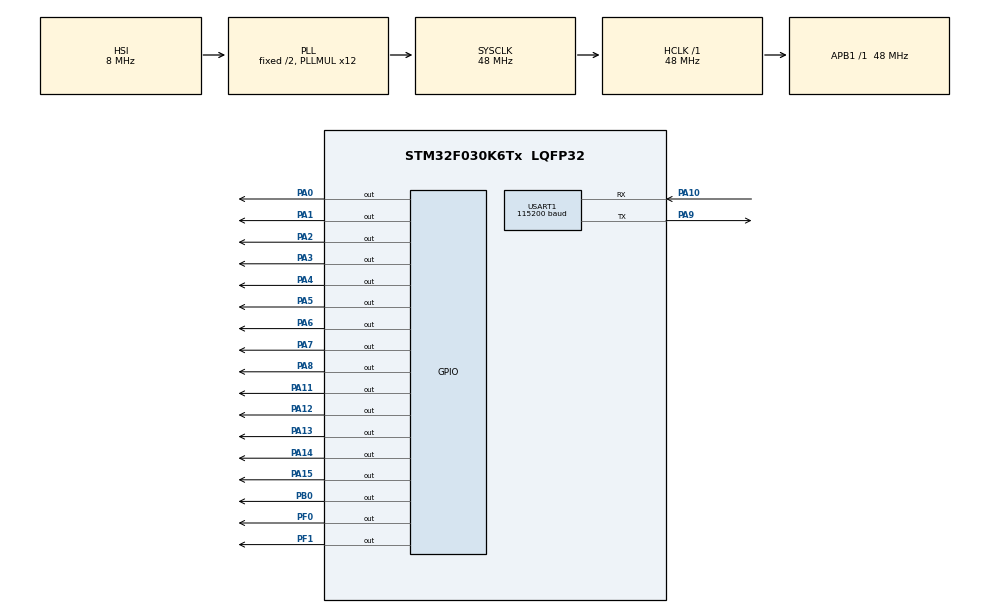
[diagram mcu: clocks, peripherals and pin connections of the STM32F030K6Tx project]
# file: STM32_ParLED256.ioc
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Dma.Request0=TIM1_CH1
Dma.Request1=TIM1_CH2
Dma.Request2=TIM1_CH4/TRIG/COM
Dma.Request3=TIM1_CH3/UP
Dma.TIM1_CH1.0.Direction=DMA_MEMORY_TO_PERIPH
Dma.TIM1_CH1.0.Instance=DMA1_Channel2
Dma.TIM1_CH1.0.MemDataAlignment=DMA_MDATAALIGN_WORD
Dma.TIM1_CH1.0.MemInc=DMA_MINC_ENABLE
Dma.TIM1_CH1.0.Mode=DMA_CIRCULAR
Dma.TIM1_CH1.0.PeriphDataAlignment=DMA_PDATAALIGN_WORD
Dma.TIM1_CH1.0.PeriphInc=DMA_PINC_DISABLE
Dma.TIM1_CH1.0.Priority=DMA_PRIORITY_HIGH
Dma.TIM1_CH2.1.Direction=DMA_MEMORY_TO_PERIPH
Dma.TIM1_CH2.1.Instance=DMA1_Channel3
Dma.TIM1_CH2.1.MemDataAlignment=DMA_MDATAALIGN_WORD
Dma.TIM1_CH2.1.MemInc=DMA_MINC_ENABLE
Dma.TIM1_CH2.1.Mode=DMA_CIRCULAR
Dma.TIM1_CH2.1.PeriphDataAlignment=DMA_PDATAALIGN_WORD
Dma.TIM1_CH2.1.PeriphInc=DMA_PINC_DISABLE
Dma.TIM1_CH2.1.Priority=DMA_PRIORITY_HIGH
Dma.TIM1_CH3/UP.3.Direction=DMA_MEMORY_TO_PERIPH
Dma.TIM1_CH3/UP.3.Instance=DMA1_Channel5
Dma.TIM1_CH3/UP.3.MemDataAlignment=DMA_MDATAALIGN_WORD
Dma.TIM1_CH3/UP.3.MemInc=DMA_MINC_ENABLE
Dma.TIM1_CH3/UP.3.Mode=DMA_CIRCULAR
Dma.TIM1_CH3/UP.3.PeriphDataAlignment=DMA_PDATAALIGN_WORD
Dma.TIM1_CH3/UP.3.PeriphInc=DMA_PINC_DISABLE
Dma.TIM1_CH3/UP.3.Priority=DMA_PRIORITY_HIGH
Dma.TIM1_CH4/TRIG/COM.2.Direction=DMA_MEMORY_TO_PERIPH
Dma.TIM1_CH4/TRIG/COM.2.Instance=DMA1_Channel4
Dma.TIM1_CH4/TRIG/COM.2.MemDataAlignment=DMA_MDATAALIGN_WORD
Dma.TIM1_CH4/TRIG/COM.2.MemInc=DMA_MINC_ENABLE
Dma.TIM1_CH4/TRIG/COM.2.Mode=DMA_CIRCULAR
Dma.TIM1_CH4/TRIG/COM.2.PeriphDataAlignment=DMA_PDATAALIGN_WORD
Dma.TIM1_CH4/TRIG/COM.2.PeriphInc=DMA_PINC_DISABLE
Dma.TIM1_CH4/TRIG/COM.2.Priority=DMA_PRIORITY_HIGH
Mcu.Family=STM32F0
Mcu.Name=STM32F030K6Tx
Mcu.Package=LQFP32
NVIC.DMA1_Channel2_3_IRQn=true\:0\:0\:false\:false\:true\:false\:true\:true
NVIC.DMA1_Channel4_5_IRQn=true\:0\:0\:false\:false\:true\:false\:true\:true
NVIC.TIM1_BRK_UP_TRG_COM_IRQn=true\:1\:0\:true\:false\:true\:true\:true\:true
NVIC.TIM3_IRQn=true\:0\:0\:false\:false\:true\:true\:true\:true
PA0.GPIO_ModeDefaultOutputPP=GPIO_MODE_OUTPUT_PP
PA0.GPIO_PuPd=GPIO_NOPULL
PA0.GPIO_Speed=GPIO_SPEED_FREQ_HIGH
PA0.Signal=GPIO_Output
PA1.GPIO_Speed=GPIO_SPEED_FREQ_HIGH
PA1.Signal=GPIO_Output
PA10.Mode=Asynchronous
PA10.Signal=USART1_RX
PA11.GPIO_Speed=GPIO_SPEED_FREQ_HIGH
PA11.Signal=GPIO_Output
PA12.GPIO_Speed=GPIO_SPEED_FREQ_HIGH
PA12.Signal=GPIO_Output
PA13.GPIO_Speed=GPIO_SPEED_FREQ_HIGH
PA13.Signal=GPIO_Output
PA14.GPIO_Speed=GPIO_SPEED_FREQ_HIGH
PA14.Signal=GPIO_Output
PA15.GPIO_Speed=GPIO_SPEED_FREQ_HIGH
PA15.Signal=GPIO_Output
PA2.GPIO_Speed=GPIO_SPEED_FREQ_HIGH
PA2.Signal=GPIO_Output
PA3.GPIO_Speed=GPIO_SPEED_FREQ_HIGH
PA3.Signal=GPIO_Output
PA4.GPIO_Speed=GPIO_SPEED_FREQ_HIGH
PA4.Signal=GPIO_Output
PA5.GPIO_Speed=GPIO_SPEED_FREQ_HIGH
PA5.Signal=GPIO_Output
PA6.GPIO_Speed=GPIO_SPEED_FREQ_HIGH
PA6.Signal=GPIO_Output
PA7.GPIO_Speed=GPIO_SPEED_FREQ_HIGH
PA7.Signal=GPIO_Output
PA8.GPIO_Speed=GPIO_SPEED_FREQ_HIGH
PA8.Signal=GPIO_Output
PA9.Mode=Asynchronous
PA9.Signal=USART1_TX
PB0.GPIO_Speed=GPIO_SPEED_FREQ_HIGH
PB0.Signal=GPIO_Output
PF0-OSC_IN.GPIO_Speed=GPIO_SPEED_FREQ_HIGH
PF0-OSC_IN.Signal=GPIO_Output
PF1-OSC_OUT.GPIO_Speed=GPIO_SPEED_FREQ_HIGH
PF1-OSC_OUT.Signal=GPIO_Output
ProjectManager.HeapSize=0x200
ProjectManager.StackSize=0x400
ProjectManager.TargetToolchain=CMake
RCC.AHBFreq_Value=48000000
RCC.APB1Freq_Value=48000000
RCC.APB1TimFreq_Value=48000000
RCC.HCLKFreq_Value=48000000
RCC.PLLMUL=RCC_PLL_MUL12
RCC.SYSCLKFreq_VALUE=48000000
RCC.SYSCLKSource=RCC_SYSCLKSOURCE_PLLCLK
TIM1.Channel-Output\ Compare1\ No\ Output=TIM_CHANNEL_1
TIM1.Channel-Output\ Compare2\ No\ Output=TIM_CHANNEL_2
TIM1.Channel-Output\ Compare3\ No\ Output=TIM_CHANNEL_3
TIM1.Channel-Output\ Compare4\ No\ Output=TIM_CHANNEL_4
TIM1.Period=999
TIM1.Prescaler=5
TIM3.Period=19999
USART1.BaudRate=115200
USART1.VirtualMode-Asynchronous=VM_ASYNC
VP_TIM1_VS_ClockSourceINT.Mode=Internal
VP_TIM1_VS_no_output1.Mode=Output Compare1 No Output
VP_TIM1_VS_no_output2.Mode=Output Compare2 No Output
VP_TIM1_VS_no_output3.Mode=Output Compare3 No Output
VP_TIM1_VS_no_output4.Mode=Output Compare4 No Output
VP_TIM3_VS_ClockSourceINT.Mode=Internal
board=custom

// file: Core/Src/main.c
/* USER CODE BEGIN Header */
/**
  ******************************************************************************
  * @file           : main.c
  * @brief          : Main program body
  ******************************************************************************
  * @attention
  *
  * Copyright (c) 2025 STMicroelectronics.
  * All rights reserved.
  *
  * This software is licensed under terms that can be found in the LICENSE file
  * in the root directory of this software component.
  * If no LICENSE file comes with this software, it is provided AS-IS.
  *
  ******************************************************************************
  */
/* USER CODE END Header */
#include "main.h"

/* USER CODE BEGIN PM */
#include "main.h"
#include "matrixLED.h"

#define NUM_FRAMES 536

const uint16_t led_animation[NUM_FRAMES][16] ={
  { 0xFF0F, 0xFF87, 0xFF07, 0xFE07, 0xFE03, 0xFE03, 0xFE03, 0xFF03, 0xFF03, 0xF883, 0xF883, 0xF887, 0xFC03, 0xFC07, 0xFC03, 0xFC01 },
  { 0xFF0F, 0xFF87, 0xFF07, 0xFE07, 0xFE03, 0xFE03, 0xFE03, 0xFF03, 0xFF03, 0xF883, 0xF883, 0xF887, 0xFC03, 0xFC07, 0xFC07, 0xFC01 },
  { 0xFF0F, 0xFF87, 0xFF07, 0xFE07, 0xFE03, 0xFE03, 0xFE03, 0xFF03, 0xFF03, 0xF983, 0xF883, 0xF887, 0xFC03, 0xFC07, 0xFC07, 0xFC01 },
  { 0xFF0F, 0xFF87, 0xFF07, 0xFE07, 0xFE03, 0xFE03, 0xFE03, 0xFF03, 0xFF03, 0xF9C3, 0xF943, 0xF887, 0xF803, 0xFC07, 0xFC07, 0xFC01 },
  { 0xFF0F, 0xFF07, 0xFF07, 0xFE07, 0xFE03, 0xFE03, 0xFE03, 0xFF03, 0xFF03, 0xFDC3, 0xF943, 0xF887, 0xF803, 0xFC07, 0xFC07, 0xFC05 },
  { 0xFF0F, 0xFF07, 0xFF07, 0xFE07, 0xFE03, 0xFE03, 0xFE03, 0xFF03, 0xFF03, 0xF943, 0xF943, 0xF987, 0xF803, 0xFC07, 0xFC07, 0xFC07 },
  { 0xFF0F, 0xFF07, 0xFF07, 0xFE07, 0xFE03, 0xFE03, 0xFE03, 0xFF03, 0xFF03, 0xFF43, 0xF943, 0xF987, 0xF803, 0xF807, 0xFC07, 0xFC07 },
  { 0xFE0F, 0xFF07, 0xFF07, 0xFE07, 0xFE03, 0xFE03, 0xFE03, 0xFF03, 0xFF03, 0xFF03, 0xF943, 0xF987, 0xF883, 0xF887, 0xFC07, 0xFC07 },
  { 0xFE0F, 0xFF07, 0xFE07, 0xFE07, 0xFE03, 0xFE03, 0xFE03, 0xFF03, 0xFF03, 0xFF03, 0xF947, 0xF987, 0xF983, 0xF887, 0xFC07, 0xFC07 },
  { 0xFE0F, 0xFE07, 0xFE07, 0xFE07, 0xFE03, 0xFE03, 0xFE03, 0xFF03, 0xFF03, 0xFF03, 0xFB47, 0xF187, 0xF183, 0xF887, 0xFC07, 0xFC07 },
  { 0xFE0F, 0xFE07, 0xFE07, 0xFE07, 0xFE03, 0xFE03, 0xFE03, 0xFF03, 0xFF03, 0xFF03, 0xFF03, 0xF387, 0xF183, 0xF087, 0xF807, 0xFC07 },
  { 0xFC0F, 0xFE0F, 0xFE07, 0xFE07, 0xFC03, 0xFC03, 0xFE03, 0xFF03, 0xFF03, 0xFF03, 0xFF03, 0xFB87, 0xF383, 0xF187, 0xF007, 0xF807 },
  { 0xFC0F, 0xFC0F, 0xFE07, 0xFC07, 0xFC07, 0xFC03, 0xFC03, 0xFF03, 0xFF03, 0xFF03, 0xFF07, 0xFF87, 0xF383, 0xE387, 0xE183, 0xF003 },
  { 0xFC0F, 0xFC0F, 0xFE07, 0xFC07, 0xFC07, 0xFC03, 0xFC03, 0xFF03, 0xFF03, 0xFF03, 0xFF07, 0xFF07, 0xFF83, 0xE783, 0xE383, 0xE003 },
  { 0xF81F, 0xFC0F, 0xFE07, 0xFC07, 0xFC07, 0xFC07, 0xFC03, 0xFE03, 0xFF03, 0xFF03, 0xFF07, 0xFF07, 0xFF83, 0xF783, 0xE783, 0xE007 },
  { 0xF81F, 0xF80F, 0xFC0F, 0xFC07, 0xFC07, 0xFC07, 0xFC03, 0xFE03, 0xFF03, 0xFF03, 0xFF07, 0xFF03, 0xFF03, 0xFF83, 0xE787, 0xE781 },
  { 0xF81F, 0xF80F, 0xFC0F, 0xFC07, 0xFC07, 0xFC07, 0xFC07, 0xFE03, 0xFF03, 0xFF03, 0xFF07, 0xFF03, 0xFF03, 0xFF87, 0xFF81, 0xE781 },
  { 0xF91F, 0xF80F, 0xF80F, 0xFC07, 0xFC07, 0xFC07, 0xFC07, 0xFC03, 0xFF03, 0xFF03, 0xFF03, 0xFF03, 0xFF03, 0xFF01, 0xFF81, 0xFF81 },
  { 0xFF9F, 0xF80F, 0xF80F, 0xFC07, 0xFC07, 0xFC07, 0xFC07, 0xFC03, 0xFF03, 0xFF83, 0xFF83, 0xFF83, 0xFF83, 0xFF81, 0xFF81, 0xFF83 },
  { 0xFF9F, 0xF80F, 0xF80F, 0xFC07, 0xFC07, 0xFC07, 0xFC07, 0xFC03, 0xFE03, 0xFF03, 0xFF83, 0xFEC3, 0xFF83, 0xFF81, 0xFF81, 0xFF81 },
  { 0xFFFF, 0xFC0F, 0xF80F, 0xFC07, 0xFC07, 0xFC07, 0xFC07, 0xFC03, 0xFE03, 0xFF03, 0xFF83, 0xFEC3, 0xFFC3, 0xFF83, 0xFF81, 0xFF81 },
  { 0xFFFF, 0xFE8F, 0xFC0F, 0xFC07, 0xFE07, 0xFC07, 0xFC07, 0xFC03, 0xFE03, 0xFF03, 0xFF03, 0xFEC3, 0xFEC3, 0xFFC1, 0xFFC1, 0xFFC1 },
  { 0xFFFF, 0xFFCF, 0xFC07, 0xFC07, 0xFE07, 0xFE03, 0xFE03, 0xFE03, 0xFE03, 0xFF03, 0xFF03, 0xFF03, 0xFEE1, 0xFFC1, 0xFFC1, 0xFFC0 },
  { 0xFFFF, 0xFFEF, 0xFE07, 0xFE07, 0xFE03, 0xFE03, 0xFE03, 0xFE03, 0xFE03, 0xFF03, 0xFF03, 0xFF23, 0xFF61, 0xFFE1, 0xFFC1, 0xFFC0 },
  { 0xFFFF, 0xFFFF, 0xFF07, 0xFF03, 0xFF03, 0xFF03, 0xFE03, 0xFE03, 0xFE01, 0xFF81, 0xFF81, 0xFF21, 0xFF61, 0xFF61, 0xFFE0, 0xFFC0 },
  { 0xFFFF, 0xFFFF, 0xFF87, 0xFF03, 0xFF83, 0xFF01, 0xFF01, 0xFF01, 0xFF01, 0xFF81, 0xFF81, 0xFF81, 0xFF21, 0xFF60, 0xFF60, 0xFFE0 },
  { 0xFFFF, 0xFFFF, 0xFFCB, 0xFF81, 0xFF81, 0xFF81, 0xFF01, 0xFF01, 0xFF01, 0xFF81, 0xFFC1, 0xFF81, 0xFFB1, 0xFFB0, 0xFF60, 0xFFE0 },
  { 0xFFFF, 0xFFFF, 0xFFC7, 0xFFC1, 0xFF81, 0xFF80, 0xFF80, 0xFF80, 0xFF80, 0xFFC0, 0xFFC0, 0xFFC0, 0xFF90, 0xFFB0, 0xFFF0, 0xFFE0 },
  { 0xFFFF, 0xFFF7, 0xFFE1, 0xFFE0, 0xFFC0, 0xFF80, 0xFF80, 0xFF80, 0xFFC0, 0xFFC0, 0xFFC0, 0xFFD0, 0xFFD0, 0xFFD0, 0xFFF0, 0xFFF0 },
  { 0xFFFF, 0xFFF3, 0xFFF0, 0xFFE0, 0xFFC0, 0xFFC0, 0xFFC0, 0xFFC0, 0xFFC0, 0xFFE0, 0xFFE0, 0xFFE0, 0xFFE0, 0xFFF0, 0xFFF0, 0xFFF0 },
  { 0xFFF9, 0xFFF8, 0xFFF0, 0xFFE0, 0xFFC0, 0xFFC0, 0xFFC0, 0xFFE0, 0xFFE0, 0xFFE0, 0xFFE0, 0xFFE0, 0xFFF8, 0xFFF8, 0xFFF8, 0xFFF0 },
  { 0xFFFC, 0xFFF8, 0xFFF0, 0xFFE0, 0xFFE0, 0xFFE0, 0xFFE0, 0xFFE0, 0xFFF0, 0xFFF0, 0xFFF8, 0xFFF8, 0xFFF8, 0xFFF8, 0xFFF8, 0xFFF8 },
  { 0xFFFE, 0xFFF8, 0xFFF0, 0xFFF0, 0xFFE0, 0xFFE0, 0xFFF0, 0xFFF0, 0xFFF0, 0xFFF0, 0xFFF0, 0xFFF8, 0xFFF8, 0xFFF8, 0xFFF8, 0xFFF8 },
  { 0xFFFF, 0xFFF8, 0xFFF0, 0xFFF0, 0xFFF0, 0xFFF0, 0xFFF0, 0xFFF0, 0xFFF8, 0xFFFC, 0xFFF8, 0xFFF8, 0xFFF8, 0xFFF8, 0xFFF0, 0xFFF8 },
  { 0xFFFF, 0xFFFC, 0xFFF8, 0xFFF8, 0xFFF8, 0xFFF8, 0xFFF8, 0xFFF8, 0xFFF8, 0xFFF8, 0xFFF8, 0xFFF8, 0xFFF8, 0xFFF0, 0xFFE0, 0xFFE0 },
  { 0xFFFF, 0xFFFC, 0xFFFC, 0xFFF8, 0xFFF8, 0xFFF8, 0xFFF8, 0xFFFC, 0xFFFE, 0xFFF8, 0xFFF8, 0xFFF0, 0xFFE0, 0xFFC0, 0xFF80, 0xFF00 },
  { 0xFFFF, 0xFFFE, 0xFFFC, 0xFFFC, 0xFFFC, 0xFFFC, 0xFFFC, 0xFFFC, 0xFFFC, 0xFFF0, 0xFFC0, 0xFF00, 0xEC00, 0xC400, 0xC000, 0xE000 },
  { 0xFFFF, 0xFFFE, 0xFFFC, 0xFFFC, 0xFFFC, 0xFFFC, 0xFFFC, 0xCFFC, 0xC5FC, 0xC000, 0xC000, 0xC000, 0xE810, 0xF810, 0xF810, 0xF800 },
  { 0xFFFF, 0xE7FE, 0xE7FC, 0xC7FC, 0xE1FC, 0xE0F8, 0xC078, 0xF80C, 0xF004, 0xF000, 0xE020, 0xE030, 0xE020, 0xE020, 0xE020, 0xFE60 },
  { 0xE07F, 0xF07F, 0xFE3E, 0xFC3C, 0xF81C, 0xF018, 0xE008, 0xE000, 0xE004, 0xE030, 0xF030, 0xF870, 0xFE70, 0xFFE0, 0xFFE0, 0xFFE0 },
  { 0xFF3F, 0xFFBF, 0xFF1F, 0xE01F, 0xE01E, 0xE01C, 0xF00C, 0xF00C, 0xF800, 0xF800, 0xFC20, 0xFC78, 0xFFF0, 0xFFF0, 0xFFF0, 0xFFF0 },
  { 0xFFDF, 0xFFCF, 0xFFCF, 0xF9CF, 0xF9CF, 0xF80F, 0xFC0F, 0xFC0E, 0xFC0E, 0xFC0E, 0xFC04, 0xFC00, 0xFC00, 0xFE00, 0xFFF8, 0xFFF8 },
  { 0xFFFF, 0xFFFF, 0xFFFF, 0xFFFF, 0xFFF7, 0xFF77, 0xFF27, 0xFF27, 0xFF27, 0xFE07, 0xFE0F, 0xFE06, 0xFE06, 0xFE06, 0xFE00, 0xFE00 },
  { 0xFFFF, 0xFFFF, 0xFFFF, 0xFFFF, 0xFFFF, 0xFFFF, 0xFFFF, 0xFFFF, 0xFFFB, 0xFFC3, 0xFFC7, 0xFF87, 0xFF87, 0xFF87, 0xFF07, 0xFF07 },
  { 0xFFFF, 0xFFFF, 0xFFFF, 0xFFFF, 0xFFFF, 0xFFFF, 0xFFFF, 0xFFFF, 0xFFFF, 0xFFFF, 0xFFFF, 0xFFFF, 0xFFF9, 0xFFF1, 0xFFF3, 0xFFE3 },
  { 0xFFFF, 0xFFFF, 0xFFFF, 0xFFFF, 0xFFFF, 0xFFFF, 0xFFFF, 0xFFFF, 0xFFFF, 0xFFFF, 0xFFFF, 0xFFFF, 0xFFFF, 0xFFFF, 0xFFFF, 0xFFFF },
  { 0xFFFF, 0xFFFF, 0xFFFF, 0xFFFF, 0xFFFF, 0xFFFF, 0xFFFF, 0xFFFF, 0xFFFF, 0xFFFF, 0xFFFF, 0xFFFF, 0xFFFF, 0xFFFF, 0xFFFF, 0xFFFF },
  { 0xFCFF, 0xFFFF, 0xFFFF, 0xFFFF, 0xFFFF, 0xFFFF, 0xFFFF, 0xFFFF, 0xFFFF, 0xFFFF, 0xFFFF, 0xFFFF, 0xFFFF, 0xFFFF, 0xFFFF, 0xFFFF },
  { 0xFCFF, 0xFCFF, 0xFFFF, 0xFFFF, 0xFFFF, 0xFFFF, 0xFFFF, 0xFFFF, 0xFFFF, 0xFFFF, 0xFFFF, 0xFFFF, 0xFFFF, 0xFFFF, 0xFFFF, 0xFFFF },
  { 0xFC7F, 0xFCFF, 0xFFFF, 0xFFFF, 0xFFFF, 0xFFFF, 0xFFFF, 0xFFFF, 0xFFFF, 0xFFFF, 0xFFFF, 0xFFFF, 0xFFFF, 0xFFFF, 0xFFFF, 0xFFFF },
  { 0xFC7F, 0xFC7F, 0xFCFF, 0xFFFF, 0xFFFF, 0xFFFF, 0xFFFF, 0xFFFF, 0xFFFF, 0xFFFF, 0xFFFF, 0xFFFF, 0xFFFF, 0xFFFF, 0xFFFF, 0xFFFF },
  { 0xFC7F, 0xFC7F, 0xFC7F, 0xFE7F, 0xFFFF, 0xFFFF, 0xFFFF, 0xFFFF, 0xFFFF, 0xFFFF, 0xFFFF, 0xFFFF, 0xFFFF, 0xFFFF, 0xFFFF, 0xFFFF },
  { 0xFEFF, 0xFC7F, 0xFC7F, 0xFC7F, 0xFE7F, 0xFFFF, 0xFFFF, 0xFFFF, 0xFFFF, 0xFFFF, 0xFFFF, 0xFFFF, 0xFFFF, 0xFFFF, 0xFFFF, 0xFFFF },
  { 0xFFFF, 0xFE7F, 0xFC7F, 0xFC7F, 0xFC7F, 0xFFFF, 0xFFFF, 0xFFFF, 0xFFFF, 0xFFFF, 0xFFFF, 0xFFFF, 0xFFFF, 0xFFFF, 0xFFFF, 0xFFFF },
  { 0xFFFF, 0xFFFF, 0xFC7F, 0xFC3F, 0xFC3F, 0xFE7F, 0xFFFF, 0xFFFF, 0xFFFF, 0xFFFF, 0xFFFF, 0xFFFF, 0xFFFF, 0xFFFF, 0xFFFF, 0xFFFF },
  { 0xFFFF, 0xFFFF, 0xFE7F, 0xFC3F, 0xFC3F, 0xFC3F, 0xFE7F, 0xFFFF, 0xFFFF, 0xFFFF, 0xFFFF, 0xFFFF, 0xFFFF, 0xFFFF, 0xFFFF, 0xFFFF },
  { 0xFFFF, 0xFFFF, 0xFFFF, 0xFE7F, 0xFC3F, 0xFC3F, 0xFE7F, 0xFF7F, 0xFFFF, 0xFFFF, 0xFFFF, 0xFFFF, 0xFFFF, 0xFFFF, 0xFFFF, 0xFFFF },
  { 0xFFFF, 0xFFFF, 0xFFFF, 0xFE7F, 0xFE3F, 0xFC3F, 0xFC3F, 0xFE7F, 0xFFFF, 0xFFFF, 0xFFFF, 0xFFFF, 0xFFFF, 0xFFFF, 0xFFFF, 0xFFFF },
  { 0xFFFF, 0xFFFF, 0xFFFF, 0xFFFF, 0xFE3F, 0xFC3F, 0xFC3F, 0xFE3F, 0xFE7F, 0xFFFF, 0xFFFF, 0xFFFF, 0xFFFF, 0xFFFF, 0xFFFF, 0xFFFF },
  { 0xFFFF, 0xFFFF, 0xFFFF, 0xFFFF, 0xFF7F, 0xFE3F, 0xFC3F, 0xFC3F, 0xFE3F, 0xFF7F, 0xFFFF, 0xFFFF, 0xFFFF, 0xFFFF, 0xFFFF, 0xFFFF },
  { 0xFFFF, 0xFFFF, 0xFFFF, 0xFFFF, 0xFFFF, 0xFE3F, 0xFE3F, 0xFE3F, 0xFE3F, 0xFE7F, 0xFFFF, 0xFFFF, 0xFFFF, 0xFFFF, 0xFFFF, 0xFFFF },
  { 0xFFFF, 0xFFFF, 0xFFFF, 0xFFFF, 0xFFFF, 0xFF7F, 0xFC3F, 0xFE3F, 0xFE3F, 0xFE3F, 0xFFFF, 0xFFFF, 0xFFFF, 0xFFFF, 0xFFFF, 0xFFFF },
  { 0xFFFF, 0xFFFF, 0xFFFF, 0xFFFF, 0xFFFF, 0xFFFF, 0xFE3F, 0xFC3F, 0xFE3F, 0xFE3F, 0xFE3F, 0xFFFF, 0xFFFF, 0xFFFF, 0xFFFF, 0xFFFF },
  { 0xFFFF, 0xFFFF, 0xFFFF, 0xFFFF, 0xFFFF, 0xFFFF, 0xFE7F, 0xFE3F, 0xFE1F, 0xFE1F, 0xFE3F, 0xFFFF, 0xFFFF, 0xFFFF, 0xFFFF, 0xFFFF },
  { 0xFFFF, 0xFFFF, 0xFFFF, 0xFFFF, 0xFFFF, 0xFFFF, 0xFFFF, 0xFE3F, 0xFE1F, 0xFE1F, 0xFE3F, 0xFF3F, 0xFFFF, 0xFFFF, 0xFFFF, 0xFFFF },
  { 0xFFFF, 0xFFFF, 0xFFFF, 0xFFFF, 0xFFFF, 0xFFFF, 0xFFFF, 0xFF3F, 0xFE1F, 0xFE1F, 0xFE1F, 0xFF3F, 0xFFFF, 0xFFFF, 0xFFFF, 0xFFFF },
  { 0xFFFF, 0xFFFF, 0xFFFF, 0xFFFF, 0xFFFF, 0xFFFF, 0xFFFF, 0xFF3F, 0xFE1F, 0xFE1F, 0xFE1F, 0xFE3F, 0xFE3F, 0xFFFF, 0xFFFF, 0xFFFF },
  { 0xFFFF, 0xFFFF, 0xFFFF, 0xFFFF, 0xFFFF, 0xFFFF, 0xFFFF, 0xFFFF, 0xFE3F, 0xFE1F, 0xFE1F, 0xFE1F, 0xFF3F, 0xFFFF, 0xFFFF, 0xFFFF },
  { 0xFFFF, 0xFFFF, 0xFFFF, 0xFFFF, 0xFFFF, 0xFFFF, 0xFFFF, 0xFFFF, 0xFF3F, 0xFE1F, 0xFE1F, 0xFE1F, 0xFE3F, 0xFFFF, 0xFFFF, 0xFFFF },
  { 0xFFFF, 0xFFFF, 0xFFFF, 0xFFFF, 0xFFFF, 0xFFFF, 0xFFFF, 0xFFFF, 0xFF3F, 0xFE3F, 0xFE1F, 0xFE1F, 0xFE3F, 0xFF3F, 0xFFFF, 0xFFFF },
  { 0xFFFF, 0xFFFF, 0xFFFF, 0xFFFF, 0xFFFF, 0xFFFF, 0xFFFF, 0xFFFF, 0xFF7F, 0xFE3F, 0xFE1F, 0xFE1F, 0xFE3F, 0xFF7F, 0xFFFF, 0xFFFF },
  { 0xFFFF, 0xFFFF, 0xFFFF, 0xFFFF, 0xFFFF, 0xFFFF, 0xFFFF, 0xFFFF, 0xFF7F, 0xFE3F, 0xFE1F, 0xFE1F, 0xFE3F, 0xFF1F, 0xFFFF, 0xFFFF },
  { 0xFFFF, 0xFFFF, 0xFFFF, 0xFFFF, 0xFFFF, 0xFFFF, 0xFFFF, 0xFFFF, 0xFFFF, 0xFE3F, 0xFE1F, 0xFE1F, 0xFE1F, 0xFF3F, 0xFFFF, 0xFFFF },
  { 0xFFFF, 0xFFFF, 0xFFFF, 0xFFFF, 0xFFFF, 0xFFFF, 0xFFFF, 0xFFFF, 0xFFFF, 0xFE1F, 0xFE1F, 0xFE1F, 0xFE1F, 0xFF3F, 0xFFFF, 0xFFFF },
  { 0xFFFF, 0xFFFF, 0xFFFF, 0xFFFF, 0xFFFF, 0xFFFF, 0xFFFF, 0xFFFF, 0xFFBF, 0xFE3F, 0xFE1F, 0xFE1F, 0xFE1F, 0xFF3F, 0xFFFF, 0xFFFF },
  { 0xFFFF, 0xFFFF, 0xFFFF, 0xFFFF, 0xFFFF, 0xFFFF, 0xFFFF, 0xFFFF, 0xFF3F, 0xFE1F, 0xFE1F, 0xFE1F, 0xFE1F, 0xFF3F, 0xFFFF, 0xFFFF },
  { 0xFFFF, 0xFFFF, 0xFFFF, 0xFFFF, 0xFFFF, 0xFFFF, 0xFFFF, 0xFFFF, 0xFF3F, 0xFE3F, 0xFE1F, 0xFE1F, 0xFE1F, 0xFF3F, 0xFFFF, 0xFFFF },
  { 0xFFFF, 0xFFFF, 0xFFFF, 0xFFFF, 0xFFFF, 0xFFFF, 0xFFFF, 0xFFFF, 0xFE3F, 0xFE1F, 0xFE1F, 0xFE1F, 0xFE3F, 0xFF7F, 0xFFFF, 0xFFFF },
  { 0xFFFF, 0xFFFF, 0xFFFF, 0xFFFF, 0xFFFF, 0xFFFF, 0xFFFF, 0xFFFF, 0xFE3F, 0xFE1F, 0xFE1F, 0xFE1F, 0xFE3F, 0xFFFF, 0xFFFF, 0xFFFF },
  { 0xFFFF, 0xFFFF, 0xFFFF, 0xFFFF, 0xFFFF, 0xFFFF, 0xFFFF, 0xFF3F, 0xFE1F, 0xFE1F, 0xFE1F, 0xFE1F, 0xFE3F, 0xFFFF, 0xFFFF, 0xFFFF },
  { 0xFFFF, 0xFFFF, 0xFFFF, 0xFFFF, 0xFFFF, 0xFFFF, 0xFFFF, 0xFF3F, 0xFE1F, 0xFE1F, 0xFE1F, 0xFE1F, 0xFF7F, 0xFFFF, 0xFFFF, 0xFFFF },
  { 0xFFFF, 0xFFFF, 0xFFFF, 0xFFFF, 0xFFFF, 0xFFFF, 0xFF7F, 0xFE3F, 0xFE1F, 0xFC1F, 0xFE1F, 0xFE3F, 0xFFFF, 0xFFFF, 0xFFFF, 0xFFFF },
  { 0xFFFF, 0xFFFF, 0xFFFF, 0xFFFF, 0xFFFF, 0xFFFF, 0xFF3F, 0xFC3F, 0xFE1F, 0xFC1F, 0xFE3F, 0xFF3F, 0xFFFF, 0xFFFF, 0xFFFF, 0xFFFF },
  { 0xFFFF, 0xFFFF, 0xFFFF, 0xFFFF, 0xFFFF, 0xFFFF, 0xFE3F, 0xFE1F, 0xFE1F, 0xFE1F, 0xFE3F, 0xFFFF, 0xFFFF, 0xFFFF, 0xFFFF, 0xFFFF },
  { 0xFFFF, 0xFFFF, 0xFFFF, 0xFFFF, 0xFFFF, 0xFF7F, 0xFE3F, 0xFE1F, 0xFC1F, 0xFE1F, 0xFE3F, 0xFFFF, 0xFFFF, 0xFFFF, 0xFFFF, 0xFFFF },
  { 0xFFFF, 0xFFFF, 0xFFFF, 0xFFFF, 0xFFFF, 0xFE3F, 0xFC3F, 0xFC1F, 0xFE1F, 0xFE3F, 0xFE7F, 0xFFFF, 0xFFFF, 0xFFFF, 0xFFFF, 0xFFFF },
  { 0xFFFF, 0xFFFF, 0xFFFF, 0xFFFF, 0xFFFF, 0xFE3F, 0xFC1F, 0xFC1F, 0xFE1F, 0xFC3F, 0xFF7F, 0xFFFF, 0xFFFF, 0xFFFF, 0xFFFF, 0xFFFF },
  { 0xFFFF, 0xFFFF, 0xFFFF, 0xFFFF, 0xFF7F, 0xFE3F, 0xFC1F, 0xFC1F, 0xFE3F, 0xFE3F, 0xFFFF, 0xFFFF, 0xFFFF, 0xFFFF, 0xFFFF, 0xFFFF },
  { 0xFFFF, 0xFFFF, 0xFFFF, 0xFFFF, 0xFE3F, 0xFE3F, 0xFC1F, 0xFC1F, 0xFC3F, 0xFF3F, 0xFFFF, 0xFFFF, 0xFFFF, 0xFFFF, 0xFFFF, 0xFFFF },
  { 0xFFFF, 0xFFFF, 0xFFFF, 0xFFFF, 0xFE3F, 0xFE3F, 0xFC1F, 0xFC1F, 0xFC3F, 0xFF7F, 0xFFFF, 0xFFFF, 0xFFFF, 0xFFFF, 0xFFFF, 0xFFFF },
  { 0xFFFF, 0xFFFF, 0xFFFF, 0xFFFF, 0xFE3F, 0xFC3F, 0xFC1F, 0xFC1F, 0xFE3F, 0xFFFF, 0xFFFF, 0xFFFF, 0xFFFF, 0xFFFF, 0xFFFF, 0xFFFF },
  { 0xFFFF, 0xFFFF, 0xFFFF, 0xFF7F, 0xFE3F, 0xFC3F, 0xFC1F, 0xFC1F, 0xFE3F, 0xFEBF, 0xFFFF, 0xFFFF, 0xFFFF, 0xFFFF, 0xFFFF, 0xFFFF },
  { 0xFFFF, 0xFFFF, 0xFFFF, 0xFFFF, 0xFE3F, 0xFC1F, 0xFC1F, 0xFC3F, 0xFE3F, 0xFF7F, 0xFFFF, 0xFFFF, 0xFFFF, 0xFFFF, 0xFFFF, 0xFFFF },
  { 0xFFFF, 0xFFFF, 0xFFFF, 0xFFFF, 0xFE3F, 0xFC1F, 0xFC1F, 0xFC3F, 0xFE3F, 0xFF7F, 0xFFFF, 0xFFFF, 0xFFFF, 0xFFFF, 0xFFFF, 0xFFFF },
  { 0xFFFF, 0xFFFF, 0xFFFF, 0xFFFF, 0xFE3F, 0xFC3F, 0xFC3F, 0xFC3F, 0xFE3F, 0xFF3F, 0xFFFF, 0xFFFF, 0xFFFF, 0xFFFF, 0xFFFF, 0xFFFF },
  { 0xFFFF, 0xFFFF, 0xFFFF, 0xFFFF, 0xFE3F, 0xFC3F, 0xFC1F, 0xFC1F, 0xFE3F, 0xFF7F, 0xFFFF, 0xFFFF, 0xFFFF, 0xFFFF, 0xFFFF, 0xFFFF },
  { 0xFFFF, 0xFFFF, 0xFFFF, 0xFFFF, 0xFE3F, 0xFC1F, 0xFC1F, 0xFC1F, 0xFE1F, 0xFE7F, 0xFFFF, 0xFFFF, 0xFFFF, 0xFFFF, 0xFFFF, 0xFFFF },
  { 0xFFFF, 0xFFFF, 0xFFFF, 0xFFFF, 0xFE1F, 0xFE3F, 0xFC1F, 0xFC1F, 0xFE1F, 0xFE3F, 0xFFFF, 0xFFFF, 0xFFFF, 0xFFFF, 0xFFFF, 0xFFFF },
  { 0xFFFF, 0xFFFF, 0xFFFF, 0xFFFF, 0xFE3F, 0xFE1F, 0xFC1F, 0xFC1F, 0xFE1F, 0xFE3F, 0xFFFF, 0xFFFF, 0xFFFF, 0xFFFF, 0xFFFF, 0xFFFF },
  { 0xFFFF, 0xFFFF, 0xFFFF, 0xFFFF, 0xFE3F, 0xFE1F, 0xFC1F, 0xFC1F, 0xFE1F, 0xFE3F, 0xFFFF, 0xFFFF, 0xFFFF, 0xFFFF, 0xFFFF, 0xFFFF },
  { 0xFFFF, 0xFFFF, 0xFFFF, 0xFFFF, 0xFFFF, 0xFE1F, 0xFC1F, 0xFE1F, 0xFE1F, 0xFE3F, 0xFFFF, 0xFFFF, 0xFFFF, 0xFFFF, 0xFFFF, 0xFFFF },
  { 0xFFFF, 0xFFFF, 0xFFFF, 0xFFFF, 0xFF3F, 0xFE1F, 0xFC1F, 0xFC1F, 0xFE1F, 0xFE1F, 0xFF7F, 0xFFFF, 0xFFFF, 0xFFFF, 0xFFFF, 0xFFFF },
  { 0xFFFF, 0xFFFF, 0xFFFF, 0xFFFF, 0xFFBF, 0xFE1F, 0xFE1F, 0xFC1F, 0xFE1F, 0xFE1F, 0xFF7F, 0xFFFF, 0xFFFF, 0xFFFF, 0xFFFF, 0xFFFF },
  { 0xFFFF, 0xFFFF, 0xFFFF, 0xFFFF, 0xFFBF, 0xFE1F, 0xFE1F, 0xFC1F, 0xFE1F, 0xFE1F, 0xFF3F, 0xFFFF, 0xFFFF, 0xFFFF, 0xFFFF, 0xFFFF },
  { 0xFFFF, 0xFFFF, 0xFFFF, 0xFFFF, 0xFFFF, 0xFF1F, 0xFE1F, 0xFE0F, 0xFE1F, 0xFE1F, 0xFF3F, 0xFFFF, 0xFFFF, 0xFFFF, 0xFFFF, 0xFFFF },
  { 0xFFFF, 0xFFFF, 0xFFFF, 0xFFFF, 0xFFFF, 0xFF3F, 0xFE1F, 0xFE0F, 0xFE1F, 0xFE1F, 0xFF1F, 0xFFFF, 0xFFFF, 0xFFFF, 0xFFFF, 0xFFFF },
  { 0xFFFF, 0xFFFF, 0xFFFF, 0xFFFF, 0xFFFF, 0xFF3F, 0xFE1F, 0xFE0F, 0xFE0F, 0xFE1F, 0xFE1F, 0xFFFF, 0xFFFF, 0xFFFF, 0xFFFF, 0xFFFF },
  { 0xFFFF, 0xFFFF, 0xFFFF, 0xFFFF, 0xFFFF, 0xFF3F, 0xFE1F, 0xFE0F, 0xFE0F, 0xFE1F, 0xFE1F, 0xFFFF, 0xFFFF, 0xFFFF, 0xFFFF, 0xFFFF },
  { 0xFFFF, 0xFFFF, 0xFFFF, 0xFFFF, 0xFFFF, 0xFF1F, 0xFE1F, 0xFE0F, 0xFE0F, 0xFE1F, 0xFE1F, 0xFF3F, 0xFFFF, 0xFFFF, 0xFFFF, 0xFFFF },
  { 0xFFFF, 0xFFFF, 0xFFFF, 0xFFFF, 0xFFFF, 0xFFBF, 0xFE1F, 0xFE0F, 0xFE0F, 0xFE1F, 0xFE1F, 0xFF3F, 0xFFFF, 0xFFFF, 0xFFFF, 0xFFFF },
  { 0xFFFF, 0xFFFF, 0xFFFF, 0xFFFF, 0xFFFF, 0xFFBF, 0xFF1F, 0xFE0F, 0xFE0F, 0xFE0F, 0xFE1F, 0xFF3F, 0xFFFF, 0xFFFF, 0xFFFF, 0xFFFF },
  { 0xFFFF, 0xFFFF, 0xFFFF, 0xFFFF, 0xFFFF, 0xFFBF, 0xFF1F, 0xFE0F, 0xFE0F, 0xFE0F, 0xFE1F, 0xFF1F, 0xFFFF, 0xFFFF, 0xFFFF, 0xFFFF },
  { 0xFFFF, 0xFFFF, 0xFFFF, 0xFFFF, 0xFFFF, 0xFFFF, 0xFF1F, 0xFE1F, 0xFE0F, 0xFE0F, 0xFE1F, 0xFF1F, 0xFFFF, 0xFFFF, 0xFFFF, 0xFFFF },
  { 0xFFFF, 0xFFFF, 0xFFFF, 0xFFFF, 0xFFFF, 0xFFFF, 0xFE1F, 0xFE1F, 0xFE0F, 0xFE0F, 0xFE1F, 0xFF3F, 0xFFFF, 0xFFFF, 0xFFFF, 0xFFFF },
  { 0xFFFF, 0xFFFF, 0xFFFF, 0xFFFF, 0xFFFF, 0xFFBF, 0xFF1F, 0xFE1F, 0xFE0F, 0xFE0F, 0xFE1F, 0xFF3F, 0xFFFF, 0xFFFF, 0xFFFF, 0xFFFF },
  { 0xFFFF, 0xFFFF, 0xFFFF, 0xFFFF, 0xFFFF, 0xFFFF, 0xFE1F, 0xFE1F, 0xFE0F, 0xFE0F, 0xFE1F, 0xFF3F, 0xFFFF, 0xFFFF, 0xFFFF, 0xFFFF },
  { 0xFFFF, 0xFFFF, 0xFFFF, 0xFFFF, 0xFFFF, 0xFFFF, 0xFE1F, 0xFE1F, 0xFE0F, 0xFE1F, 0xFE1F, 0xFF3F, 0xFFFF, 0xFFFF, 0xFFFF, 0xFFFF },
  { 0xFFFF, 0xFFFF, 0xFFFF, 0xFFFF, 0xFFFF, 0xFFFF, 0xFE1F, 0xFE1F, 0xFE1F, 0xFE1F, 0xFE1F, 0xFF3F, 0xFFFF, 0xFFFF, 0xFFFF, 0xFFFF },
  { 0xFFFF, 0xFFFF, 0xFFFF, 0xFFFF, 0xFFFF, 0xFFFF, 0xFF1F, 0xFE1F, 0xFE1F, 0xFE1F, 0xFE1F, 0xFF1F, 0xFFFF, 0xFFFF, 0xFFFF, 0xFFFF },
  { 0xFFFF, 0xFFFF, 0xFFFF, 0xFFFF, 0xFFFF, 0xFFFF, 0xFF1F, 0xFE1F, 0xFE1F, 0xFE1F, 0xFE1F, 0xFF3F, 0xFFFF, 0xFFFF, 0xFFFF, 0xFFFF },
  { 0xFFFE, 0xFFFF, 0xFFFF, 0xFFFF, 0xFFFF, 0xFFFF, 0xFE1F, 0xFE1F, 0xFE1F, 0xFE1F, 0xFE1F, 0xFE3F, 0xFFFF, 0xFFFF, 0xFFFF, 0xFFFF },
  { 0xF800, 0xFFFF, 0xFFFF, 0xFFFF, 0xFFFF, 0xFFFF, 0xFE3F, 0xFE1F, 0xFE1F, 0xFE1F, 0xFE1F, 0xFE3F, 0xFFFF, 0xFFFF, 0xFFFF, 0xFFFF },
  { 0x0000, 0xC000, 0xFFFC, 0xFFFC, 0xFFFE, 0xFFFF, 0xFE3F, 0xFE1F, 0xFC1F, 0xFE1F, 0xFE1F, 0xFE3F, 0xFFFF, 0xFFFF, 0xFFFF, 0xFFFF },
  { 0x0000, 0x0000, 0x7FC0, 0xFF80, 0xFF80, 0xFFFC, 0xFF3E, 0xFC1E, 0xFC1E, 0xFC1F, 0xFE1F, 0xFE3F, 0xFFFF, 0xFFFF, 0xFFFF, 0xFFFF },
  { 0x0000, 0xFE00, 0xFE00, 0xFF00, 0xFFE0, 0xFFE1, 0xFF20, 0xFE10, 0xFC10, 0xFC10, 0xFE18, 0xFE38, 0xFFFC, 0xFFFF, 0xFFFF, 0xFFFF },
  { 0x00FF, 0x01FF, 0x01FF, 0x008F, 0x0087, 0x0086, 0x01C2, 0x01C0, 0x03E0, 0x03E0, 0x01E0, 0x00E0, 0x0000, 0x0000, 0x0000, 0x0000 },
  { 0x00FF, 0x01FF, 0x01FF, 0x008F, 0x0087, 0x0086, 0x01C2, 0x01C0, 0x03E0, 0x03E0, 0x01E0, 0x00E0, 0x0000, 0x0000, 0x0000, 0x0000 },
  { 0x00FF, 0x01FF, 0x01FF, 0x008F, 0x0087, 0x0086, 0x01C2, 0x01C0, 0x03E0, 0x03E0, 0x01E0, 0x00E0, 0x0000, 0x0000, 0x0000, 0x0000 },
  { 0x00FF, 0x01FF, 0x01FF, 0x008F, 0x0087, 0x0086, 0x01C2, 0x01C0, 0x03E0, 0x03E0, 0x01E0, 0x00E0, 0x0000, 0x0000, 0x0000, 0x0000 },
  { 0x00FF, 0x01FF, 0x01FF, 0x008F, 0x0087, 0x0086, 0x01C2, 0x01C0, 0x03E0, 0x03E0, 0x01E0, 0x00E0, 0x0000, 0x0000, 0x0000, 0x0000 },
  { 0x00FF, 0x01FF, 0x01FF, 0x008F, 0x0087, 0x0086, 0x01C2, 0x01C0, 0x03E0, 0x03E0, 0x01E0, 0x00E0, 0x0000, 0x0000, 0x0000, 0x0000 },
  { 0x00FF, 0x01FF, 0x01FF, 0x008F, 0x0087, 0x0086, 0x01C2, 0x01C0, 0x03E0, 0x03E0, 0x01E0, 0x00E0, 0x0000, 0x0000, 0x0000, 0x0000 },
  { 0x00FF, 0x01FF, 0x01FF, 0x008F, 0x0087, 0x0086, 0x01C2, 0x01C0, 0x03E0, 0x03E0, 0x01E0, 0x00E0, 0x0000, 0x0000, 0x0000, 0x0000 },
  { 0x00FF, 0x01FF, 0x01FF, 0x008F, 0x0087, 0x0086, 0x01C2, 0x01C0, 0x03E0, 0x03E0, 0x01E0, 0x00E0, 0x0000, 0x0000, 0x0000, 0x0000 },
  { 0x00FF, 0x01FF, 0x01FF, 0x008F, 0x0087, 0x0086, 0x01C2, 0x01C0, 0x03E0, 0x03E0, 0x01E0, 0x00E0, 0x0000, 0x0000, 0x0000, 0x0000 },
  { 0x00FF, 0x01FF, 0x01FF, 0x008F, 0x0087, 0x0086, 0x01C2, 0x01C0, 0x03E0, 0x03E0, 0x01E0, 0x00E0, 0x0000, 0x0000, 0x0000, 0x0000 },
  { 0x00FF, 0x01FF, 0x01FF, 0x008F, 0x0087, 0x0086, 0x01C2, 0x01C0, 0x03E0, 0x03E0, 0x01E0, 0x00E0, 0x0000, 0x0000, 0x0000, 0x0000 },
  { 0x00FF, 0x01FF, 0x01FF, 0x008F, 0x0087, 0x0086, 0x01C2, 0x01C0, 0x03E0, 0x03E0, 0x01E0, 0x00E0, 0x0000, 0x0000, 0x0000, 0x0000 },
  { 0x00FF, 0x01FF, 0x01FF, 0x008F, 0x0087, 0x0086, 0x01C2, 0x01C0, 0x03E0, 0x03E0, 0x01E0, 0x00E0, 0x0000, 0x0000, 0x0000, 0x0000 },
  { 0x3FFF, 0x07FF, 0x07FF, 0x03FF, 0x03FE, 0x07FC, 0x07F8, 0x07D0, 0x07C0, 0x07C0, 0x03C0, 0x0100, 0x0000, 0x0000, 0x0000, 0x0000 },
  { 0xFFFF, 0x3FFF, 0x1FFF, 0x0FFF, 0x1FFC, 0x3FF8, 0x7EF0, 0x7E20, 0x7E10, 0x3E00, 0x1C00, 0x0000, 0x0000, 0x0000, 0x0000, 0x0000 },
  { 0x7FFF, 0xFFFF, 0xFFFF, 0x1FFF, 0x1FFB, 0xFFF9, 0xFBF0, 0xF860, 0xF810, 0xF800, 0xF800, 0x2000, 0x0000, 0x0000, 0x0000, 0x0000 },
  { 0x6FFF, 0xFFFF, 0xFFFF, 0xFFFF, 0x7FFF, 0x7FFF, 0x7FF7, 0xE0F0, 0xE0C0, 0xE000, 0xE000, 0xC000, 0x0000, 0x0000, 0x0000, 0x0000 },
  { 0xFFC4, 0xBFED, 0x9FFF, 0xFFFF, 0xFFFF, 0xFFFF, 0xFFFF, 0x7FFF, 0x0D07, 0x0100, 0x0000, 0x0000, 0x0000, 0x0000, 0x0000, 0x0000 },
  { 0xFF80, 0xFF88, 0xFF80, 0xFFBF, 0xFFFF, 0xFFFF, 0xFFFF, 0xFFFF, 0xFFFF, 0xFE1F, 0x0201, 0x0200, 0x0000, 0x0000, 0x0000, 0x0000 },
  { 0xCC00, 0xEE00, 0xFE00, 0xFE00, 0xFF07, 0xFFFF, 0xFFFF, 0xFFFF, 0xFFFF, 0xFFFF, 0xFC7F, 0x040F, 0x0400, 0x0000, 0x0000, 0x0000 },
  { 0x0800, 0x9800, 0x9800, 0xFC00, 0xFC00, 0xFC0F, 0xFE7F, 0xFFFF, 0xFFFF, 0xFFFF, 0xFFFF, 0xFFFF, 0x081F, 0x0801, 0x0000, 0x0000 },
  { 0x0000, 0x1000, 0x3000, 0x3000, 0xF000, 0xF100, 0xFF1E, 0xFCFF, 0xFFFF, 0xFFFF, 0xFFFF, 0xFFFF, 0xFFFF, 0x3C1F, 0x1002, 0x0000 },
  { 0x0000, 0x0000, 0x2000, 0x6000, 0x6000, 0xF000, 0xF800, 0xF87C, 0xFFFE, 0xFFFE, 0xFFFF, 0xFFFF, 0xFFFF, 0xF8FE, 0x300E, 0x0002 },
  { 0x8000, 0x0000, 0x4000, 0xE000, 0xE000, 0xE000, 0xB000, 0xF070, 0xFFFC, 0xFFFC, 0xFFFE, 0xFFFF, 0xFFFF, 0xFBFF, 0x7038, 0x2000 },
  { 0x8000, 0x0000, 0x4000, 0xC000, 0xC000, 0xC000, 0xA000, 0xF470, 0xFFF8, 0xFFFC, 0xFFFE, 0xFFFE, 0xFFFE, 0xF3FE, 0xF078, 0x4000 },
  { 0x0000, 0x8000, 0x4000, 0xC000, 0xC000, 0xE000, 0xB000, 0xD420, 0xFFF8, 0xFFFC, 0xFFFE, 0xFFFE, 0xFFFF, 0xF3FF, 0xF078, 0x4004 },
  { 0x8000, 0x8000, 0x8000, 0x6000, 0xE000, 0xE000, 0xF000, 0xE800, 0xFFFC, 0xFFFC, 0xFFFE, 0xFFFF, 0xFFFF, 0xFBFF, 0xF0FD, 0x200C },
  { 0xC000, 0xC000, 0xE000, 0xE000, 0x7000, 0xF000, 0xF800, 0xEC00, 0xF77C, 0xFFFE, 0xFFFF, 0xFFFF, 0xFFFF, 0xFFFF, 0xF8FF, 0x7816 },
  { 0xC000, 0xE000, 0xE000, 0xF000, 0xB800, 0xF800, 0xF800, 0xFE00, 0xFC1C, 0xFDFF, 0xFFFF, 0xFFFF, 0xFFFF, 0xFFFF, 0xFCFF, 0xFC1F },
  { 0xE000, 0xF800, 0xF800, 0xFC00, 0xFC00, 0xFC00, 0xFC00, 0xFE00, 0xFE00, 0xFEFF, 0xFFFF, 0xFFFF, 0xFFFF, 0xFFFF, 0xFFFF, 0xFE3F },
  { 0xFC00, 0xFE00, 0xFC00, 0xFE00, 0xF600, 0xFE00, 0xFE00, 0xFE00, 0x7FE0, 0x7E47, 0x7FFF, 0xFFFF, 0xFFFF, 0xFFFF, 0xFFFF, 0xFFBF },
  { 0xFF00, 0xFF00, 0xFF00, 0xFE00, 0xFD00, 0xFF00, 0xFB80, 0xFF80, 0xFFC0, 0x9F70, 0xBFDF, 0xFFFF, 0xFFFF, 0xFFFF, 0xFFFF, 0xFFFF },
  { 0xFF80, 0x3FC0, 0x3F60, 0x7F80, 0x7F00, 0x7FC0, 0x7FC0, 0xFFC0, 0xFFC0, 0xEFF8, 0x4FE7, 0xDFFF, 0xFFFF, 0xFFFF, 0x7FFF, 0x7FFF },
  { 0x3FF0, 0x1FF8, 0x0FC0, 0x1FA0, 0x1FC0, 0x9F60, 0x9F70, 0xDFF0, 0x7FF0, 0x37F8, 0x17FF, 0x27FF, 0x6FFF, 0xFFFF, 0xFFFF, 0x3FFF },
  { 0x1FFC, 0x0FFE, 0x07F0, 0x07C0, 0xC7E0, 0xC7A0, 0xEFB0, 0x77FC, 0x1FFC, 0x1FFC, 0x0DFF, 0x1BF9, 0x13FF, 0xB7FF, 0xFFFF, 0x1FFF },
  { 0x07FE, 0x07FF, 0x03FA, 0x03FC, 0x33F0, 0x73E0, 0x73E8, 0x1BEE, 0x0FFE, 0x07FE, 0x06FF, 0x04FE, 0x0DFF, 0x09FF, 0xFFFF, 0xFFFF },
  { 0x03FE, 0x03FF, 0x03FE, 0x00FE, 0x18FD, 0x39FC, 0x19F4, 0x0DF5, 0x07F7, 0x03FF, 0x01FF, 0x027F, 0x027F, 0x04FF, 0x8DFF, 0xFFFF },
  { 0x03FF, 0x01FF, 0x01FF, 0x00FF, 0x0CFF, 0x0CFC, 0x0CF8, 0x0EFA, 0x03FB, 0x01FF, 0x00FF, 0x01BF, 0x013F, 0x027F, 0x02FF, 0xFFFF },
  { 0x03FF, 0x01FF, 0x00FF, 0x007F, 0x047F, 0x067E, 0x0E7E, 0x06F8, 0x017F, 0x01FF, 0x00FF, 0x009F, 0x009F, 0x013F, 0x013F, 0xC37F },
  { 0x03FF, 0x01FF, 0x00FF, 0x00FF, 0x003F, 0x067D, 0x067E, 0x077C, 0x01FD, 0x00FD, 0x007F, 0x005F, 0x009F, 0x009F, 0x013F, 0x037F },
  { 0x03FF, 0x01FF, 0x00FF, 0x007F, 0x003F, 0x033F, 0x073E, 0x037F, 0x01FD, 0x00FF, 0x007F, 0x007F, 0x004F, 0x00CF, 0x009F, 0x01BF },
  { 0x03FF, 0x01FF, 0x00FF, 0x007F, 0x003F, 0x031F, 0x033F, 0x033F, 0x01BE, 0x00FE, 0x007F, 0x002F, 0x006F, 0x004F, 0x00CF, 0x009F },
  { 0x03FF, 0x01FF, 0x00FF, 0x007F, 0x001F, 0x011F, 0x031F, 0x033F, 0x01BE, 0x00FE, 0x007F, 0x003F, 0x002F, 0x0067, 0x004F, 0x00CF },
  { 0x03FF, 0x01FF, 0x00FF, 0x007F, 0x003F, 0x011F, 0x039F, 0x039F, 0x01BF, 0x00FF, 0x007F, 0x003F, 0x003F, 0x0027, 0x0067, 0x004F },
  { 0x03FF, 0x01FF, 0x00FF, 0x007F, 0x003F, 0x001F, 0x019F, 0x039F, 0x019F, 0x00FF, 0x007F, 0x003F, 0x003F, 0x0027, 0x0067, 0x0047 },
  { 0x03FF, 0x01FF, 0x00FF, 0x007F, 0x003F, 0x003F, 0x019F, 0x039F, 0x019F, 0x00FF, 0x005F, 0x007F, 0x003F, 0x0037, 0x0027, 0x0067 },
  { 0x03FF, 0x01FF, 0x00FF, 0x007F, 0x003F, 0x003F, 0x019F, 0x039F, 0x019F, 0x00DF, 0x007F, 0x007F, 0x003F, 0x003F, 0x0027, 0x0027 },
  { 0x03FF, 0x03FF, 0x01FF, 0x007F, 0x007F, 0x003F, 0x019F, 0x039F, 0x039F, 0x01DF, 0x007F, 0x007F, 0x003F, 0x003F, 0x0037, 0x0027 },
  { 0x07FF, 0x03FF, 0x01FF, 0x00FF, 0x007F, 0x003F, 0x019F, 0x038F, 0x039F, 0x019F, 0x007F, 0x005F, 0x007F, 0x003F, 0x003F, 0x0027 },
  { 0x07FF, 0x07FF, 0x01FF, 0x01FF, 0x007F, 0x003F, 0x01BF, 0x039F, 0x039F, 0x019F, 0x00DF, 0x007F, 0x007F, 0x007F, 0x003F, 0x0027 },
  { 0x0FFE, 0x07FF, 0x03FF, 0x01FF, 0x007F, 0x007F, 0x013F, 0x039F, 0x039F, 0x019F, 0x00DF, 0x007F, 0x007F, 0x007F, 0x007F, 0x003F },
  { 0x0FFF, 0x07FF, 0x03FF, 0x01FF, 0x00FF, 0x007F, 0x013F, 0x039F, 0x039F, 0x039F, 0x00DF, 0x007F, 0x007F, 0x007F, 0x007F, 0x007F },
  { 0x0FFF, 0x07FF, 0x03FF, 0x01FF, 0x00FF, 0x007F, 0x007F, 0x01BF, 0x039F, 0x039F, 0x009F, 0x007F, 0x007F, 0x007F, 0x007F, 0x007F },
  { 0x0FFF, 0x07FF, 0x03FF, 0x01FF, 0x00FF, 0x007F, 0x007F, 0x01BF, 0x039F, 0x039F, 0x019F, 0x00FF, 0x007F, 0x007F, 0x007F, 0x007F },
  { 0x0FFF, 0x07FF, 0x03FF, 0x01FF, 0x00FF, 0x007F, 0x007F, 0x01BF, 0x039F, 0x039F, 0x019F, 0x007F, 0x007F, 0x007F, 0x007F, 0x007F },
  { 0x07FF, 0x07FF, 0x03FF, 0x01FF, 0x00FF, 0x007F, 0x007F, 0x01BF, 0x039F, 0x039F, 0x019F, 0x005F, 0x007F, 0x007F, 0x007F, 0x007F },
  { 0x07FF, 0x07FF, 0x03FF, 0x01FF, 0x00FF, 0x007F, 0x007F, 0x01BF, 0x039F, 0x019F, 0x01DF, 0x005F, 0x007F, 0x007F, 0x007F, 0x007F },
  { 0x07FF, 0x07FF, 0x03FF, 0x01FF, 0x00FF, 0x00FF, 0x007F, 0x01FF, 0x01BF, 0x019F, 0x01DF, 0x005F, 0x007F, 0x007F, 0x007F, 0x007F },
  { 0x07FF, 0x07FF, 0x03FF, 0x01FF, 0x00FF, 0x00FF, 0x007F, 0x00FF, 0x01FF, 0x01DF, 0x01DF, 0x005F, 0x007F, 0x007F, 0x007F, 0x007F },
  { 0x07FF, 0x03FF, 0x03FF, 0x01FF, 0x00FF, 0x00FF, 0x007F, 0x00FF, 0x01FF, 0x01DF, 0x01DF, 0x005F, 0x007F, 0x007F, 0x007F, 0x007F },
  { 0x077F, 0x07FF, 0x03FF, 0x01FF, 0x00FF, 0x00FF, 0x007F, 0x007F, 0x01FF, 0x01DF, 0x01DF, 0x00DF, 0x007F, 0x007F, 0x007F, 0x007F },
  { 0x073F, 0x07FF, 0x03FF, 0x01FF, 0x01FF, 0x00FF, 0x007F, 0x007F, 0x00FF, 0x01DF, 0x01DF, 0x00DF, 0x007F, 0x007F, 0x007F, 0x007F },
  { 0x0F3F, 0x07FF, 0x03FF, 0x03FF, 0x01FF, 0x00FF, 0x00FF, 0x007F, 0x00FF, 0x01DF, 0x01DF, 0x00DF, 0x007F, 0x007F, 0x003F, 0x003F },
  { 0x0F3F, 0x07FF, 0x07FF, 0x03FE, 0x01FF, 0x00FF, 0x00FF, 0x007F, 0x00FF, 0x01DF, 0x01DF, 0x00FF, 0x007F, 0x003F, 0x003F, 0x003F },
  { 0x0E3F, 0x0FFF, 0x07FF, 0x07FE, 0x03FE, 0x01FF, 0x00FF, 0x007F, 0x00FF, 0x01FF, 0x01DF, 0x00FF, 0x007F, 0x003F, 0x003F, 0x003F },
  { 0x063F, 0x0E7F, 0x0FFF, 0x07FE, 0x03FE, 0x01FF, 0x00FF, 0x007F, 0x00FF, 0x01FF, 0x01DF, 0x00FF, 0x007F, 0x003F, 0x003F, 0x003F },
  { 0x0E3E, 0x167F, 0x1FFF, 0x0FFC, 0x07FC, 0x03FF, 0x01FF, 0x007F, 0x00FF, 0x01FF, 0x01FF, 0x00FF, 0x007F, 0x003F, 0x003F, 0x003F },
  { 0x0E7E, 0x067F, 0x1EFF, 0x1FFC, 0x0FFC, 0x03FF, 0x01FF, 0x00FF, 0x00FF, 0x00FF, 0x01FF, 0x00FF, 0x007F, 0x003F, 0x003F, 0x003F },
  { 0x0F7E, 0x0E7E, 0x06FF, 0x1FFC, 0x1FFC, 0x07FF, 0x01FF, 0x01FF, 0x00FF, 0x00FF, 0x01FF, 0x00FF, 0x007F, 0x003E, 0x003F, 0x003F },
  { 0x0C7C, 0x0E7E, 0x0CFB, 0x07F8, 0x1FFC, 0x0FFF, 0x03FF, 0x01FF, 0x00FF, 0x00FF, 0x01FF, 0x00FF, 0x007F, 0x003E, 0x003E, 0x003F },
  { 0x087C, 0x0C7E, 0x0CFB, 0x07F8, 0x1FF8, 0x1FFF, 0x07FF, 0x01FF, 0x00FF, 0x00FF, 0x01FF, 0x00FF, 0x007D, 0x003E, 0x003E, 0x003F },
  { 0x0038, 0x087E, 0x1CFF, 0x0DF9, 0x1FF8, 0x1FFF, 0x07FF, 0x01FF, 0x00FF, 0x00FF, 0x01FF, 0x00FF, 0x007F, 0x007E, 0x003E, 0x003E },
  { 0x0038, 0x007C, 0x00FE, 0x1DF9, 0x0FF8, 0x1FFE, 0x07FF, 0x01FF, 0x00FF, 0x00FF, 0x01FF, 0x00FF, 0x007E, 0x007F, 0x007F, 0x007F },
  { 0x0010, 0x007C, 0x00FE, 0x0DFB, 0x0FF8, 0x0FFE, 0x07FF, 0x01FF, 0x00FF, 0x01FF, 0x01BF, 0x00FF, 0x007F, 0x007D, 0x007F, 0x007F },
  { 0x0000, 0x0078, 0x00FC, 0x0CF3, 0x0FF8, 0x0FFC, 0x07FF, 0x01FF, 0x00FF, 0x01BF, 0x01BF, 0x00FF, 0x007D, 0x007D, 0x007D, 0x005F },
  { 0x0000, 0x0078, 0x00FC, 0x06F6, 0x0FF0, 0x0FFC, 0x03FF, 0x00FF, 0x00FF, 0x01BF, 0x01BF, 0x007F, 0x007D, 0x007D, 0x007D, 0x005F },
  { 0x0000, 0x0070, 0x02F8, 0x06F6, 0x0FF0, 0x0FFC, 0x03FF, 0x00FF, 0x00FF, 0x01BF, 0x01BF, 0x0079, 0x0078, 0x007F, 0x007F, 0x005F },
  { 0x0000, 0x0030, 0x0278, 0x06F4, 0x0FF0, 0x07F8, 0x01FF, 0x00FE, 0x00FF, 0x01BF, 0x01FF, 0x0078, 0x007A, 0x007F, 0x005F, 0x005F },
  { 0x0000, 0x0000, 0x0278, 0x02FC, 0x0FF0, 0x07F8, 0x01FE, 0x00FE, 0x01FF, 0x01FF, 0x00F3, 0x007A, 0x007B, 0x00FF, 0x005F, 0x009F },
  { 0x0000, 0x0000, 0x0270, 0x06F8, 0x07E0, 0x03F8, 0x01FE, 0x00FC, 0x01FF, 0x01FF, 0x00F1, 0x00FC, 0x00FF, 0x007F, 0x009F, 0x00BF },
  { 0x0000, 0x0000, 0x0070, 0x06F8, 0x07E0, 0x03F0, 0x01FC, 0x00FC, 0x01FE, 0x01FE, 0x00F0, 0x00F6, 0x00FF, 0x003F, 0x00BE, 0x003F },
  { 0x0000, 0x0000, 0x0060, 0x06F0, 0x07E0, 0x03F0, 0x01FC, 0x00FC, 0x01FE, 0x00FE, 0x00F0, 0x00F6, 0x003E, 0x00BF, 0x00BC, 0xC17F },
  { 0x0000, 0x0000, 0x0060, 0x02F0, 0x07E8, 0x03F0, 0x00F8, 0x00FC, 0x017C, 0x00F8, 0x00FC, 0x00BC, 0x00BC, 0x00B9, 0x017F, 0xFFFF },
  { 0x0000, 0x0000, 0x0040, 0x02F0, 0x03E8, 0x01F0, 0x00F8, 0x01F8, 0x017C, 0x00E0, 0x00FC, 0x003C, 0x00BF, 0x007C, 0xFDFF, 0xEFFF },
  { 0x0000, 0x0000, 0x0000, 0x02E0, 0x03C0, 0x01F0, 0x00F8, 0x017C, 0x01FC, 0x00E0, 0x00F8, 0x00BC, 0x00BB, 0xE17F, 0xFFFF, 0x10FF },
  { 0x0000, 0x0000, 0x0000, 0x02E0, 0x03C0, 0x01F0, 0x00F0, 0x0178, 0x00F0, 0x00E8, 0x00F8, 0x00BE, 0x007F, 0xFFFF, 0x10FF, 0x08FF },
  { 0x0000, 0x0000, 0x0000, 0x02E0, 0x03C0, 0x01E0, 0x00F0, 0x0178, 0x00F0, 0x00F8, 0x00F8, 0x00F2, 0xF17F, 0x7FFF, 0x08FF, 0x001D },
  { 0x0000, 0x0000, 0x0000, 0x00E0, 0x03C0, 0x01E0, 0x00F0, 0x0178, 0x00E0, 0x00F0, 0x00B8, 0x007F, 0xFFFF, 0x08FF, 0x003B, 0x0010 },
  { 0x0000, 0x0000, 0x0000, 0x02C0, 0x03C0, 0x01E0, 0x00E0, 0x0170, 0x00D0, 0x00F0, 0x00FC, 0x617F, 0x3FFF, 0x00FF, 0x0031, 0x0000 },
  { 0x0000, 0x0000, 0x0000, 0x02C0, 0x03C0, 0x00E0, 0x0160, 0x00F0, 0x00D0, 0x00F0, 0x0079, 0x7FFF, 0x08FF, 0x0037, 0x0010, 0x0000 },
  { 0x0000, 0x0000, 0x0000, 0x02C0, 0x03C0, 0x00E0, 0x0160, 0x00F0, 0x00D0, 0x00F0, 0x0077, 0x1FFF, 0x04FF, 0x0021, 0x0000, 0x0000 },
  { 0x0000, 0x0000, 0x0000, 0x01C0, 0x03C0, 0x00E0, 0x0160, 0x00E0, 0x00E0, 0x00F8, 0x317F, 0x09FF, 0x0037, 0x0000, 0x0000, 0x0000 },
  { 0x0000, 0x0000, 0x0000, 0x01C0, 0x01C0, 0x00E0, 0x0160, 0x00C0, 0x00E0, 0x0060, 0x3FFF, 0x00FF, 0x0023, 0x0000, 0x0000, 0x0000 },
  { 0x0000, 0x0000, 0x0000, 0x01C0, 0x0180, 0x00E0, 0x0170, 0x00C0, 0x00E0, 0x007E, 0x1FFF, 0x00FF, 0x0023, 0x0000, 0x0000, 0x0000 },
  { 0x0000, 0x0000, 0x0000, 0x01C0, 0x0180, 0x00E0, 0x0160, 0x00E0, 0x00F0, 0x207E, 0x1FFF, 0x002F, 0x0000, 0x0000, 0x0000, 0x0000 },
  { 0x0000, 0x0000, 0x0000, 0x01C0, 0x0180, 0x00E0, 0x01E0, 0x00E0, 0x0070, 0x107E, 0x04FF, 0x0026, 0x0000, 0x0000, 0x0000, 0x0000 },
  { 0x0000, 0x0000, 0x0000, 0x01C0, 0x0180, 0x00E0, 0x01C0, 0x00E0, 0x0070, 0x1DFE, 0x00FF, 0x0022, 0x0000, 0x0000, 0x0000, 0x0000 },
  { 0x0000, 0x0000, 0x0000, 0x0180, 0x0180, 0x00E0, 0x00C0, 0x00E0, 0x0070, 0x1FFE, 0x00DE, 0x0000, 0x0000, 0x0000, 0x0000, 0x0000 },
  { 0x0000, 0x0000, 0x0000, 0x0180, 0x0180, 0x00E0, 0x00C0, 0x00E0, 0x0064, 0x0FFE, 0x001E, 0x0000, 0x0000, 0x0000, 0x0000, 0x0000 },
  { 0x0000, 0x0000, 0x0000, 0x0180, 0x0180, 0x00C0, 0x00C0, 0x0040, 0x006C, 0x0DFE, 0x004E, 0x0000, 0x0000, 0x0000, 0x0000, 0x0000 },
  { 0x0000, 0x0000, 0x0000, 0x0180, 0x0180, 0x00C0, 0x00C0, 0x0040, 0x18FC, 0x04FC, 0x0044, 0x0000, 0x0000, 0x0000, 0x0000, 0x0000 },
  { 0x0000, 0x0000, 0x0000, 0x0080, 0x0180, 0x00C0, 0x00C0, 0x0040, 0x0CFC, 0x00FC, 0x0040, 0x0000, 0x0000, 0x0000, 0x0000, 0x0000 },
  { 0x0000, 0x0000, 0x0000, 0x0000, 0x0180, 0x00C0, 0x0080, 0x0040, 0x0FFC, 0x027C, 0x0000, 0x0000, 0x0000, 0x0000, 0x0000, 0x0000 },
  { 0x0000, 0x0000, 0x0000, 0x0000, 0x0180, 0x00C0, 0x0080, 0x0060, 0x07FC, 0x005C, 0x0000, 0x0000, 0x0000, 0x0000, 0x0000, 0x0000 },
  { 0x0000, 0x0000, 0x0000, 0x0000, 0x0180, 0x00C0, 0x0080, 0x0040, 0x07F8, 0x0048, 0x0000, 0x0000, 0x0000, 0x0000, 0x0000, 0x0000 },
  { 0x0000, 0x0000, 0x0000, 0x0000, 0x0180, 0x00C0, 0x00C0, 0x0040, 0x00F8, 0x0008, 0x0000, 0x0000, 0x0000, 0x0000, 0x0000, 0x0000 },
  { 0x0000, 0x0000, 0x0000, 0x0000, 0x0180, 0x00C0, 0x00C0, 0x00F8, 0x02F8, 0x0000, 0x0000, 0x0000, 0x0000, 0x0000, 0x0000, 0x0000 },
  { 0x0000, 0x0000, 0x0000, 0x0000, 0x0180, 0x00C0, 0x00C0, 0x00F0, 0x00F8, 0x0000, 0x0000, 0x0000, 0x0000, 0x0000, 0x0000, 0x0000 },
  { 0x0000, 0x0000, 0x0000, 0x0000, 0x0180, 0x00C0, 0x00C0, 0x04F0, 0x0078, 0x0000, 0x0000, 0x0000, 0x0000, 0x0000, 0x0000, 0x0000 },
  { 0x0000, 0x0000, 0x0000, 0x0000, 0x0080, 0x00C0, 0x00C0, 0x04F0, 0x0078, 0x0000, 0x0000, 0x0000, 0x0000, 0x0000, 0x0000, 0x0000 },
  { 0x0000, 0x0000, 0x0000, 0x0000, 0x0080, 0x00C0, 0x00C0, 0x06F0, 0x0058, 0x0000, 0x0000, 0x0000, 0x0000, 0x0000, 0x0000, 0x0000 },
  { 0x0000, 0x0000, 0x0000, 0x0000, 0x0080, 0x00C0, 0x00C0, 0x07F0, 0x0050, 0x0000, 0x0000, 0x0000, 0x0000, 0x0000, 0x0000, 0x0000 },
  { 0x0000, 0x0000, 0x0000, 0x0100, 0x0080, 0x00C0, 0x0040, 0x07F0, 0x0050, 0x0000, 0x0000, 0x0000, 0x0000, 0x0000, 0x0000, 0x0000 },
  { 0x0000, 0x0000, 0x0000, 0x0000, 0x0080, 0x00C0, 0x0040, 0x07F0, 0x0050, 0x0000, 0x0000, 0x0000, 0x0000, 0x0000, 0x0000, 0x0000 },
  { 0x0000, 0x0000, 0x0000, 0x0000, 0x0080, 0x00C0, 0x0040, 0x03F0, 0x0040, 0x0000, 0x0000, 0x0000, 0x0000, 0x0000, 0x0000, 0x0000 },
  { 0x0000, 0x0000, 0x0000, 0x0000, 0x0080, 0x00C0, 0x0040, 0x03F0, 0x0040, 0x0000, 0x0000, 0x0000, 0x0000, 0x0000, 0x0000, 0x0000 },
  { 0x0000, 0x0000, 0x0000, 0x0000, 0x0080, 0x00C0, 0x0040, 0x03F0, 0x0040, 0x0000, 0x0000, 0x0000, 0x0000, 0x0000, 0x0000, 0x0000 },
  { 0x0000, 0x0000, 0x0000, 0x0000, 0x0080, 0x00C0, 0x0040, 0x03F0, 0x0040, 0x0000, 0x0000, 0x0000, 0x0000, 0x0000, 0x0000, 0x0000 },
  { 0x0000, 0x0000, 0x0000, 0x0000, 0x0080, 0x00C0, 0x0040, 0x03F0, 0x0000, 0x0000, 0x0000, 0x0000, 0x0000, 0x0000, 0x0000, 0x0000 },
  { 0x0000, 0x0000, 0x0000, 0x0000, 0x0080, 0x00C0, 0x0040, 0x03F0, 0x0000, 0x0000, 0x0000, 0x0000, 0x0000, 0x0000, 0x0000, 0x0000 },
  { 0x0000, 0x0000, 0x0000, 0x0000, 0x0080, 0x00C0, 0x0040, 0x03F0, 0x0000, 0x0000, 0x0000, 0x0000, 0x0000, 0x0000, 0x0000, 0x0000 },
  { 0x0000, 0x0000, 0x0000, 0x0000, 0x0080, 0x00C0, 0x0040, 0x01F0, 0x0000, 0x0000, 0x0000, 0x0000, 0x0000, 0x0000, 0x0000, 0x0000 },
  { 0x0000, 0x0000, 0x0000, 0x0000, 0x0080, 0x00C0, 0x0040, 0x01F0, 0x0000, 0x0000, 0x0000, 0x0000, 0x0000, 0x0000, 0x0000, 0x0000 },
  { 0x0000, 0x0000, 0x0000, 0x0100, 0x0080, 0x00C0, 0x0040, 0x03F0, 0x0000, 0x0000, 0x0000, 0x0000, 0x0000, 0x0000, 0x0000, 0x0000 },
  { 0x0000, 0x0000, 0x0000, 0x0000, 0x0080, 0x00C0, 0x0040, 0x03F0, 0x0000, 0x0000, 0x0000, 0x0000, 0x0000, 0x0000, 0x0000, 0x0000 },
  { 0x0000, 0x0000, 0x0000, 0x0000, 0x0080, 0x00C0, 0x00C0, 0x02F0, 0x0000, 0x0000, 0x0000, 0x0000, 0x0000, 0x0000, 0x0000, 0x0000 },
  { 0x0000, 0x0000, 0x0000, 0x0000, 0x0080, 0x00C0, 0x00C0, 0x02F0, 0x0000, 0x0000, 0x0000, 0x0000, 0x0000, 0x0000, 0x0000, 0x0000 },
  { 0x0000, 0x0000, 0x0000, 0x0080, 0x0080, 0x00C0, 0x0080, 0x02F0, 0x0000, 0x0000, 0x0000, 0x0000, 0x0000, 0x0000, 0x0000, 0x0000 },
  { 0x0000, 0x0000, 0x0000, 0x0180, 0x0080, 0x0080, 0x0080, 0x02F0, 0x0000, 0x0000, 0x0000, 0x0000, 0x0000, 0x0000, 0x0000, 0x0000 },
  { 0x0000, 0x0000, 0x0000, 0x0180, 0x0080, 0x0080, 0x0080, 0x02F0, 0x0000, 0x0000, 0x0000, 0x0000, 0x0000, 0x0000, 0x0000, 0x0000 },
  { 0x0000, 0x0000, 0x0000, 0x0180, 0x0080, 0x0080, 0x0080, 0x00F0, 0x0000, 0x0000, 0x0000, 0x0000, 0x0000, 0x0000, 0x0000, 0x0000 },
  { 0x0000, 0x0000, 0x0000, 0x0180, 0x0080, 0x0080, 0x0080, 0x00F0, 0x0000, 0x0000, 0x0000, 0x0000, 0x0000, 0x0000, 0x0000, 0x0000 },
  { 0x0000, 0x0000, 0x0000, 0x0180, 0x0080, 0x0080, 0x0080, 0x00F0, 0x0000, 0x0000, 0x0000, 0x0000, 0x0000, 0x0000, 0x0000, 0x0000 },
  { 0x0000, 0x0000, 0x0000, 0x0080, 0x0080, 0x0080, 0x00C0, 0x00F0, 0x0000, 0x0000, 0x0000, 0x0000, 0x0000, 0x0000, 0x0000, 0x0000 },
  { 0x0000, 0x0000, 0x0000, 0x0080, 0x0080, 0x0080, 0x00C0, 0x00F0, 0x0000, 0x0000, 0x0000, 0x0000, 0x0000, 0x0000, 0x0000, 0x0000 },
  { 0x0000, 0x0000, 0x0000, 0x0080, 0x0080, 0x0080, 0x0080, 0x02F0, 0x0000, 0x0000, 0x0000, 0x0000, 0x0000, 0x0000, 0x0000, 0x0000 },
  { 0x0000, 0x0000, 0x0000, 0x0080, 0x0080, 0x0080, 0x0090, 0x02F0, 0x0000, 0x0000, 0x0000, 0x0000, 0x0000, 0x0000, 0x0000, 0x0000 },
  { 0x0000, 0x0000, 0x0000, 0x0080, 0x0080, 0x0080, 0x0090, 0x02F0, 0x0000, 0x0000, 0x0000, 0x0000, 0x0000, 0x0000, 0x0000, 0x0000 },
  { 0x0000, 0x0000, 0x0000, 0x0080, 0x0080, 0x0080, 0x0090, 0x00B0, 0x0000, 0x0000, 0x0000, 0x0000, 0x0000, 0x0000, 0x0000, 0x0000 },
  { 0x0000, 0x0000, 0x0000, 0x0080, 0x0080, 0x0080, 0x00B0, 0x00B0, 0x0000, 0x0000, 0x0000, 0x0000, 0x0000, 0x0000, 0x0000, 0x0000 },
  { 0x0000, 0x0000, 0x0000, 0x0080, 0x0080, 0x0080, 0x00B0, 0x00F0, 0x0000, 0x0000, 0x0000, 0x0000, 0x0000, 0x0000, 0x0000, 0x0000 },
  { 0x0000, 0x0000, 0x0000, 0x0080, 0x0080, 0x0080, 0x00B0, 0x02F0, 0x0000, 0x0000, 0x0000, 0x0000, 0x0000, 0x0000, 0x0000, 0x0000 },
  { 0x0000, 0x0000, 0x0000, 0x0080, 0x0080, 0x0080, 0x00B0, 0x02F0, 0x0000, 0x0000, 0x0000, 0x0000, 0x0000, 0x0000, 0x0000, 0x0000 },
  { 0x0000, 0x0000, 0x0000, 0x0080, 0x0080, 0x0080, 0x00B0, 0x02F0, 0x0000, 0x0000, 0x0000, 0x0000, 0x0000, 0x0000, 0x0000, 0x0000 },
  { 0x0000, 0x0000, 0x0000, 0x0080, 0x0080, 0x0080, 0x0090, 0x02F0, 0x0000, 0x0000, 0x0000, 0x0000, 0x0000, 0x0000, 0x0000, 0x0000 },
  { 0x0000, 0x0000, 0x0000, 0x0080, 0x0080, 0x0080, 0x0080, 0x02F0, 0x0000, 0x0000, 0x0000, 0x0000, 0x0000, 0x0000, 0x0000, 0x0000 },
  { 0x0000, 0x0000, 0x0000, 0x0080, 0x0080, 0x0080, 0x0080, 0x02F0, 0x0000, 0x0000, 0x0000, 0x0000, 0x0000, 0x0000, 0x0000, 0x0000 },
  { 0x0000, 0x0000, 0x0000, 0x0080, 0x0080, 0x0080, 0x0080, 0x02F0, 0x0000, 0x0000, 0x0000, 0x0000, 0x0000, 0x0000, 0x0000, 0x0000 },
  { 0x0000, 0x0000, 0x0000, 0x0080, 0x0080, 0x0080, 0x0080, 0x02F0, 0x0000, 0x0000, 0x0000, 0x0000, 0x0000, 0x0000, 0x0000, 0x0000 },
  { 0x0000, 0x0000, 0x0000, 0x0080, 0x0180, 0x0080, 0x00C0, 0x02F0, 0x0000, 0x0000, 0x0000, 0x0000, 0x0000, 0x0000, 0x0000, 0x0000 },
  { 0x0000, 0x0000, 0x0000, 0x0000, 0x0180, 0x0080, 0x00C0, 0x03F0, 0x0000, 0x0000, 0x0000, 0x0000, 0x0000, 0x0000, 0x0000, 0x0000 },
  { 0x0000, 0x0000, 0x0000, 0x0000, 0x0180, 0x0080, 0x00C0, 0x01F0, 0x0000, 0x0000, 0x0000, 0x0000, 0x0000, 0x0000, 0x0000, 0x0000 },
  { 0x0000, 0x0000, 0x0000, 0x0000, 0x0180, 0x0080, 0x00C0, 0x01F0, 0x0000, 0x0000, 0x0000, 0x0000, 0x0000, 0x0000, 0x0000, 0x0000 },
  { 0x0000, 0x0000, 0x0000, 0x0000, 0x0180, 0x0180, 0x00C0, 0x07F0, 0x0000, 0x0000, 0x0000, 0x0000, 0x0000, 0x0000, 0x0000, 0x0000 },
  { 0x0000, 0x0000, 0x0000, 0x0000, 0x0100, 0x0180, 0x0080, 0x07F0, 0x0000, 0x0000, 0x0000, 0x0000, 0x0000, 0x0000, 0x0000, 0x0000 },
  { 0x0000, 0x0000, 0x0000, 0x0000, 0x0100, 0x0180, 0x0080, 0x07F0, 0x0000, 0x0000, 0x0000, 0x0000, 0x0000, 0x0000, 0x0000, 0x0000 },
  { 0x0000, 0x0000, 0x0000, 0x0000, 0x0100, 0x0180, 0x0080, 0x07F0, 0x0010, 0x0000, 0x0000, 0x0000, 0x0000, 0x0000, 0x0000, 0x0000 },
  { 0x0000, 0x0000, 0x0000, 0x0000, 0x0100, 0x0180, 0x0080, 0x07F0, 0x0010, 0x0000, 0x0000, 0x0000, 0x0000, 0x0000, 0x0000, 0x0000 },
  { 0x0000, 0x0000, 0x0000, 0x0000, 0x0100, 0x0180, 0x0080, 0x07F0, 0x0030, 0x0000, 0x0000, 0x0000, 0x0000, 0x0000, 0x0000, 0x0000 },
  { 0x0000, 0x0000, 0x0000, 0x0000, 0x0100, 0x0180, 0x0080, 0x05F0, 0x0030, 0x0000, 0x0000, 0x0000, 0x0000, 0x0000, 0x0000, 0x0000 },
  { 0x0000, 0x0000, 0x0000, 0x0000, 0x0100, 0x0180, 0x0080, 0x05F0, 0x0030, 0x0000, 0x0000, 0x0000, 0x0000, 0x0000, 0x0000, 0x0000 },
  { 0x0000, 0x0000, 0x0000, 0x0000, 0x0100, 0x0180, 0x0080, 0x09F0, 0x0030, 0x0000, 0x0000, 0x0000, 0x0000, 0x0000, 0x0000, 0x0000 },
  { 0x0000, 0x0000, 0x0000, 0x0000, 0x0100, 0x0180, 0x0080, 0x09B0, 0x0030, 0x0000, 0x0000, 0x0000, 0x0000, 0x0000, 0x0000, 0x0000 },
  { 0x0000, 0x0000, 0x0000, 0x0000, 0x0100, 0x0180, 0x0080, 0x09B0, 0x0030, 0x0000, 0x0000, 0x0000, 0x0000, 0x0000, 0x0000, 0x0000 },
  { 0x0000, 0x0000, 0x0000, 0x0000, 0x0100, 0x0180, 0x0080, 0x01A0, 0x0030, 0x0000, 0x0000, 0x0000, 0x0000, 0x0000, 0x0000, 0x0000 },
  { 0x0000, 0x0000, 0x0000, 0x0000, 0x0180, 0x0080, 0x0080, 0x01E0, 0x0230, 0x0000, 0x0000, 0x0000, 0x0000, 0x0000, 0x0000, 0x0000 },
  { 0x0000, 0x0000, 0x0000, 0x0000, 0x0080, 0x0080, 0x0080, 0x01F0, 0x02B0, 0x0000, 0x0000, 0x0000, 0x0000, 0x0000, 0x0000, 0x0000 },
  { 0x0000, 0x0000, 0x0000, 0x0000, 0x0080, 0x0080, 0x0080, 0x01F0, 0x02B0, 0x0000, 0x0000, 0x0000, 0x0000, 0x0000, 0x0000, 0x0000 },
  { 0x0000, 0x0000, 0x0000, 0x0000, 0x0080, 0x0080, 0x0080, 0x01B0, 0x02B0, 0x0000, 0x0000, 0x0000, 0x0000, 0x0000, 0x0000, 0x0000 },
  { 0x0000, 0x0000, 0x0000, 0x0000, 0x0080, 0x0080, 0x0080, 0x01B0, 0x02B0, 0x0000, 0x0000, 0x0000, 0x0000, 0x0000, 0x0000, 0x0000 },
  { 0x0000, 0x0000, 0x0000, 0x0000, 0x0080, 0x0080, 0x0080, 0x00B0, 0x00B0, 0x0000, 0x0000, 0x0000, 0x0000, 0x0000, 0x0000, 0x0000 },
  { 0x0000, 0x0000, 0x0000, 0x0000, 0x0180, 0x0180, 0x0080, 0x00F0, 0x0030, 0x0000, 0x0000, 0x0000, 0x0000, 0x0000, 0x0000, 0x0000 },
  { 0x0000, 0x0000, 0x0000, 0x0000, 0x0180, 0x0180, 0x0080, 0x00F0, 0x0030, 0x0000, 0x0000, 0x0000, 0x0000, 0x0000, 0x0000, 0x0000 },
  { 0x0000, 0x0000, 0x0000, 0x0000, 0x0180, 0x0180, 0x0080, 0x01F0, 0x0030, 0x0000, 0x0000, 0x0000, 0x0000, 0x0000, 0x0000, 0x0000 },
  { 0x0000, 0x0000, 0x0000, 0x0000, 0x0180, 0x0180, 0x0080, 0x00F0, 0x0030, 0x0000, 0x0000, 0x0000, 0x0000, 0x0000, 0x0000, 0x0000 },
  { 0x0000, 0x0000, 0x0000, 0x0000, 0x0180, 0x01C0, 0x0080, 0x04F0, 0x0030, 0x0000, 0x0000, 0x0000, 0x0000, 0x0000, 0x0000, 0x0000 },
  { 0x0000, 0x0000, 0x0000, 0x0000, 0x0180, 0x01C0, 0x0080, 0x05F0, 0x0030, 0x0000, 0x0000, 0x0000, 0x0000, 0x0000, 0x0000, 0x0000 },
  { 0x0000, 0x0000, 0x0000, 0x0000, 0x0180, 0x01C0, 0x0080, 0x05F0, 0x0030, 0x0000, 0x0000, 0x0000, 0x0000, 0x0000, 0x0000, 0x0000 },
  { 0x0000, 0x0000, 0x0000, 0x0000, 0x0180, 0x01C0, 0x0080, 0x07F0, 0x0010, 0x0000, 0x0000, 0x0000, 0x0000, 0x0000, 0x0000, 0x0000 },
  { 0x0000, 0x0000, 0x0000, 0x0000, 0x0180, 0x01C0, 0x0080, 0x07F0, 0x0010, 0x0000, 0x0000, 0x0000, 0x0000, 0x0000, 0x0000, 0x0000 },
  { 0x0000, 0x0000, 0x0000, 0x0000, 0x0180, 0x00C0, 0x0080, 0x07F0, 0x0010, 0x0000, 0x0000, 0x0000, 0x0000, 0x0000, 0x0000, 0x0000 },
  { 0x0000, 0x0000, 0x0000, 0x0000, 0x0180, 0x00C0, 0x0080, 0x07F0, 0x0010, 0x0000, 0x0000, 0x0000, 0x0000, 0x0000, 0x0000, 0x0000 },
  { 0x0000, 0x0000, 0x0000, 0x0000, 0x0080, 0x00C0, 0x00C0, 0x07F0, 0x0010, 0x0000, 0x0000, 0x0000, 0x0000, 0x0000, 0x0000, 0x0000 },
  { 0x0000, 0x0000, 0x0000, 0x0000, 0x0080, 0x00C0, 0x00C0, 0x05F0, 0x0000, 0x0000, 0x0000, 0x0000, 0x0000, 0x0000, 0x0000, 0x0000 },
  { 0x0000, 0x0000, 0x0000, 0x0000, 0x0080, 0x00C0, 0x0040, 0x01F0, 0x0000, 0x0000, 0x0000, 0x0000, 0x0000, 0x0000, 0x0000, 0x0000 },
  { 0x0000, 0x0000, 0x0000, 0x0080, 0x0080, 0x00C0, 0x0040, 0x00F0, 0x0000, 0x0000, 0x0000, 0x0000, 0x0000, 0x0000, 0x0000, 0x0000 },
  { 0x0000, 0x0000, 0x0000, 0x0180, 0x0080, 0x00C0, 0x0040, 0x02F0, 0x0000, 0x0000, 0x0000, 0x0000, 0x0000, 0x0000, 0x0000, 0x0000 },
  { 0x0000, 0x0000, 0x0000, 0x0080, 0x0080, 0x00C0, 0x0040, 0x02F0, 0x0000, 0x0000, 0x0000, 0x0000, 0x0000, 0x0000, 0x0000, 0x0000 },
  { 0x0000, 0x0000, 0x0000, 0x0180, 0x0080, 0x00C0, 0x0060, 0x00F0, 0x0000, 0x0000, 0x0000, 0x0000, 0x0000, 0x0000, 0x0000, 0x0000 },
  { 0x0000, 0x0000, 0x0000, 0x0180, 0x0080, 0x00C0, 0x0060, 0x00F0, 0x0000, 0x0000, 0x0000, 0x0000, 0x0000, 0x0000, 0x0000, 0x0000 },
  { 0x0000, 0x0000, 0x0000, 0x0080, 0x0080, 0x00C0, 0x0050, 0x00F8, 0x0000, 0x0000, 0x0000, 0x0000, 0x0000, 0x0000, 0x0000, 0x0000 },
  { 0x0000, 0x0000, 0x0000, 0x0080, 0x00C0, 0x00C0, 0x0070, 0x00F8, 0x0000, 0x0000, 0x0000, 0x0000, 0x0000, 0x0000, 0x0000, 0x0000 },
  { 0x0000, 0x0000, 0x0000, 0x0080, 0x00C0, 0x00C0, 0x0070, 0x00F8, 0x0000, 0x0000, 0x0000, 0x0000, 0x0000, 0x0000, 0x0000, 0x0000 },
  { 0x0000, 0x0000, 0x0000, 0x0080, 0x00C0, 0x00C0, 0x0050, 0x00F0, 0x0000, 0x0000, 0x0000, 0x0000, 0x0000, 0x0000, 0x0000, 0x0000 },
  { 0x0000, 0x0000, 0x0000, 0x0080, 0x00C0, 0x00C0, 0x0050, 0x00F0, 0x0000, 0x0000, 0x0000, 0x0000, 0x0000, 0x0000, 0x0000, 0x0000 },
  { 0x0000, 0x0000, 0x0000, 0x00C0, 0x00C0, 0x0080, 0x0050, 0x00F8, 0x0000, 0x0000, 0x0000, 0x0000, 0x0000, 0x0000, 0x0000, 0x0000 },
  { 0x0000, 0x0000, 0x0000, 0x00C0, 0x00C0, 0x0040, 0x0048, 0x0178, 0x0000, 0x0000, 0x0000, 0x0000, 0x0000, 0x0000, 0x0000, 0x0000 },
  { 0x0000, 0x0000, 0x0000, 0x00C0, 0x0040, 0x0060, 0x0078, 0x017C, 0x0000, 0x0000, 0x0000, 0x0000, 0x0000, 0x0000, 0x0000, 0x0000 },
  { 0x0000, 0x0000, 0x0000, 0x00E0, 0x0060, 0x0060, 0x003C, 0x007C, 0x0000, 0x0000, 0x0000, 0x0000, 0x0000, 0x0000, 0x0000, 0x0000 },
  { 0x0000, 0x0000, 0x0000, 0x0040, 0x0060, 0x0060, 0x0064, 0x007E, 0x0000, 0x0000, 0x0000, 0x0000, 0x0000, 0x0000, 0x0000, 0x0000 },
  { 0x0000, 0x0000, 0x0000, 0x0040, 0x0060, 0x0030, 0x0034, 0x007E, 0x0000, 0x0000, 0x0000, 0x0000, 0x0000, 0x0000, 0x0000, 0x0000 },
  { 0x0000, 0x0000, 0x0000, 0x0060, 0x0030, 0x0030, 0x003A, 0x007E, 0x0012, 0x0000, 0x0000, 0x0000, 0x0000, 0x0000, 0x0000, 0x0000 },
  { 0x0000, 0x0000, 0x0000, 0x0060, 0x0030, 0x0030, 0x0012, 0x01FF, 0x0012, 0x0000, 0x0000, 0x0000, 0x0000, 0x0000, 0x0000, 0x0000 },
  { 0x0000, 0x0000, 0x0000, 0x0060, 0x0030, 0x0020, 0x0030, 0x01FF, 0x0003, 0x0000, 0x0000, 0x0000, 0x0000, 0x0000, 0x0000, 0x0000 },
  { 0x0000, 0x0000, 0x0000, 0x0060, 0x0030, 0x0038, 0x001C, 0x01FF, 0x0007, 0x0000, 0x0000, 0x0000, 0x0000, 0x0000, 0x0000, 0x0000 },
  { 0x0000, 0x0000, 0x0000, 0x0020, 0x0038, 0x0010, 0x001C, 0x01BF, 0x0007, 0x0000, 0x0000, 0x0000, 0x0000, 0x0000, 0x0000, 0x0000 },
  { 0x0000, 0x0000, 0x0000, 0x0030, 0x0018, 0x0010, 0x001C, 0x013F, 0x001F, 0x0000, 0x0000, 0x0000, 0x0000, 0x0000, 0x0000, 0x0000 },
  { 0x0000, 0x0000, 0x0000, 0x0030, 0x0018, 0x0010, 0x001C, 0x001F, 0x005F, 0x0008, 0x0000, 0x0000, 0x0000, 0x0000, 0x0000, 0x0000 },
  { 0x0000, 0x0000, 0x0000, 0x0030, 0x0018, 0x0010, 0x0018, 0x001F, 0x001F, 0x0008, 0x0000, 0x0000, 0x0000, 0x0000, 0x0000, 0x0000 },
  { 0x0000, 0x0000, 0x0000, 0x0010, 0x0018, 0x0010, 0x0018, 0x001F, 0x00DF, 0x0009, 0x0000, 0x0000, 0x0000, 0x0000, 0x0000, 0x0000 },
  { 0x0000, 0x0000, 0x0000, 0x0010, 0x0018, 0x0018, 0x0018, 0x001F, 0x007F, 0x0009, 0x0000, 0x0000, 0x0000, 0x0000, 0x0000, 0x0000 },
  { 0x0000, 0x0000, 0x0000, 0x0010, 0x0038, 0x0018, 0x0018, 0x001F, 0x007F, 0x000B, 0x0000, 0x0000, 0x0000, 0x0000, 0x0000, 0x0000 },
  { 0x0000, 0x0000, 0x0000, 0x0010, 0x0038, 0x0038, 0x0018, 0x001F, 0x007F, 0x000B, 0x0000, 0x0000, 0x0000, 0x0000, 0x0000, 0x0000 },
  { 0x0000, 0x0000, 0x0000, 0x0010, 0x0030, 0x0038, 0x0018, 0x0016, 0x007F, 0x0017, 0x0000, 0x0000, 0x0000, 0x0000, 0x0000, 0x0000 },
  { 0x0000, 0x0000, 0x0000, 0x0010, 0x0030, 0x0030, 0x0038, 0x0016, 0x007F, 0x0016, 0x0000, 0x8000, 0x8000, 0x8000, 0x8000, 0x8000 },
  { 0x0000, 0x0000, 0x0000, 0x0000, 0x0020, 0x0030, 0x0038, 0x0014, 0x007E, 0x000E, 0x0000, 0x4000, 0xC000, 0xC000, 0xC000, 0xC000 },
  { 0x0000, 0x0000, 0x0000, 0x0000, 0x0020, 0x0030, 0x0020, 0x0014, 0x007E, 0x000E, 0x0000, 0x2000, 0xE000, 0xE000, 0xE000, 0xE000 },
  { 0x0000, 0x0000, 0x0000, 0x0000, 0x0020, 0x0030, 0x0020, 0x001C, 0x003C, 0x001C, 0x0000, 0x1000, 0xD000, 0xF000, 0xF000, 0xF000 },
  { 0x0000, 0x0000, 0x0000, 0x0000, 0x0020, 0x0030, 0x0020, 0x0018, 0x003C, 0x001C, 0x0000, 0x8800, 0xC800, 0xF800, 0xF800, 0xF800 },
  { 0x0000, 0x0000, 0x0000, 0x0000, 0x0020, 0x0030, 0x0020, 0x0038, 0x0038, 0x0038, 0x8000, 0xC400, 0xC400, 0xFC00, 0xFC00, 0xFC00 },
  { 0x0000, 0x0000, 0x0000, 0x0000, 0x0020, 0x0030, 0x0020, 0x0038, 0x0038, 0x0038, 0x4000, 0x4000, 0x6000, 0xFC00, 0xFC00, 0xFC00 },
  { 0x0000, 0x0000, 0x0000, 0x0000, 0x0020, 0x0030, 0x0020, 0x0030, 0x0038, 0x0038, 0x4000, 0x4000, 0x6000, 0xFC00, 0xFC00, 0xFC00 },
  { 0x0000, 0x0000, 0x0000, 0x0000, 0x0020, 0x0030, 0x0020, 0x0030, 0x0038, 0x0038, 0x4000, 0x4000, 0x6000, 0xFC00, 0xFC00, 0xFC00 },
  { 0x0000, 0x0000, 0x0000, 0x0000, 0x0020, 0x0020, 0x0020, 0x0030, 0x0038, 0x0038, 0x4000, 0x4000, 0x6000, 0xFC00, 0xFC00, 0xFC00 },
  { 0x0000, 0x0000, 0x0000, 0x0000, 0x0020, 0x0020, 0x0020, 0x0030, 0x0078, 0x0038, 0x4000, 0x4000, 0x6000, 0xFC00, 0xFC00, 0xFC00 },
  { 0x0000, 0x0000, 0x0000, 0x0000, 0x0020, 0x0020, 0x0020, 0x0030, 0x0078, 0x0038, 0x4000, 0x4000, 0x6000, 0xFC00, 0xFC00, 0xFC00 },
  { 0x0000, 0x0000, 0x0000, 0x0000, 0x0020, 0x0020, 0x0020, 0x0038, 0x0078, 0x0038, 0x4000, 0x4000, 0x6000, 0xFC00, 0xFC00, 0xFC00 },
  { 0x0000, 0x0000, 0x0000, 0x0000, 0x0020, 0x0020, 0x0020, 0x0038, 0x0078, 0x0038, 0x4000, 0x4000, 0x6000, 0xFC00, 0xFC00, 0xFC00 },
  { 0x0000, 0x0000, 0x0000, 0x0000, 0x0020, 0x0030, 0x0030, 0x0038, 0x0078, 0x0038, 0x4000, 0x4000, 0x6000, 0xFC00, 0xFC00, 0xFC00 },
  { 0x0000, 0x0000, 0x0000, 0x0000, 0x0020, 0x0020, 0x0030, 0x0038, 0x0078, 0x0038, 0x4000, 0x4000, 0x6000, 0xFC00, 0xFC00, 0xFC00 },
  { 0x0000, 0x0000, 0x0000, 0x0000, 0x0020, 0x0020, 0x0030, 0x0038, 0x0078, 0x0030, 0x4000, 0x4000, 0x6000, 0xFC00, 0xFC00, 0xFC00 },
  { 0x0000, 0x0000, 0x0000, 0x0000, 0x0020, 0x0020, 0x0030, 0x0038, 0x0078, 0x0030, 0x4000, 0x4000, 0x6000, 0xFC00, 0xFC00, 0xFC00 },
  { 0x0000, 0x0000, 0x0000, 0x0000, 0x0020, 0x0020, 0x0030, 0x0038, 0x0078, 0x0030, 0x4000, 0x4000, 0x4000, 0xFC00, 0xFC00, 0xFC00 },
  { 0x0000, 0x0000, 0x0000, 0x0000, 0x0020, 0x0020, 0x0030, 0x0038, 0x0078, 0x0020, 0x4000, 0x4000, 0x4000, 0xFC00, 0xFC00, 0xFC00 },
  { 0x0000, 0x0000, 0x0000, 0x0000, 0x0020, 0x0020, 0x0030, 0x0038, 0x0078, 0x0000, 0x4000, 0x4000, 0x4000, 0xFC00, 0xFC00, 0xFC00 },
  { 0x0000, 0x0000, 0x0000, 0x0000, 0x0020, 0x0020, 0x0030, 0x0038, 0x0078, 0x0000, 0x4000, 0x4000, 0x4000, 0xFC00, 0xFC00, 0xFC00 },
  { 0x0000, 0x0000, 0x0000, 0x0000, 0x0020, 0x0020, 0x0030, 0x0038, 0x0078, 0x0000, 0x4000, 0x4000, 0x4200, 0xFC00, 0xFC00, 0xFC00 },
  { 0x0000, 0x0000, 0x0000, 0x0020, 0x0020, 0x0020, 0x0030, 0x0038, 0x0078, 0x0000, 0x4000, 0x4200, 0x4200, 0xFE00, 0xFE00, 0xFE00 },
  { 0x0000, 0x0000, 0x0000, 0x0020, 0x0020, 0x0020, 0x0030, 0x0038, 0x0038, 0x0000, 0x4000, 0x4200, 0x4200, 0xFE00, 0xFE00, 0xFE00 },
  { 0x0000, 0x0000, 0x0000, 0x0020, 0x0020, 0x0020, 0x0020, 0x0038, 0x0038, 0x0000, 0x4000, 0x4200, 0x4200, 0xFE00, 0xFE00, 0xFE00 },
  { 0x0000, 0x0000, 0x0000, 0x0020, 0x0020, 0x0020, 0x0020, 0x0038, 0x0038, 0x0000, 0x4000, 0x4200, 0x4200, 0xFE00, 0xFE00, 0xFE00 },
  { 0x0000, 0x0000, 0x0000, 0x0020, 0x0060, 0x0020, 0x0020, 0x0038, 0x0038, 0x0000, 0x4000, 0x4200, 0x4200, 0xFE00, 0xFE00, 0xFE00 },
  { 0x0000, 0x0000, 0x0000, 0x0020, 0x0060, 0x0020, 0x0020, 0x0038, 0x0038, 0x0000, 0x4000, 0x4200, 0x4200, 0xFE00, 0xFE00, 0xFE00 },
  { 0x0000, 0x0000, 0x0000, 0x0020, 0x0060, 0x0020, 0x0020, 0x0038, 0x0038, 0x0000, 0x4000, 0x6200, 0x5200, 0xFE00, 0xFE00, 0xFE00 },
  { 0x0000, 0x0000, 0x0000, 0x0020, 0x0060, 0x0020, 0x0020, 0x0038, 0x0038, 0x0000, 0x4000, 0x6200, 0x5200, 0xFE00, 0xFE00, 0xFE00 },
  { 0x0000, 0x0000, 0x0000, 0x0020, 0x0060, 0x0020, 0x0020, 0x0038, 0x0018, 0x0000, 0x4000, 0x6200, 0x5200, 0xFE00, 0xFE00, 0xFE00 },
  { 0x0000, 0x0000, 0x0000, 0x0020, 0x0060, 0x0020, 0x0020, 0x0038, 0x0010, 0x0000, 0x4000, 0x6200, 0x5200, 0xFE00, 0xFE00, 0xFE00 },
  { 0x0000, 0x0000, 0x0000, 0x0020, 0x0060, 0x0020, 0x0030, 0x0038, 0x0010, 0x0000, 0x4000, 0x6200, 0x7200, 0xFE00, 0xFE00, 0xFE00 },
  { 0x0000, 0x0000, 0x0000, 0x0020, 0x0060, 0x0020, 0x0020, 0x0038, 0x0010, 0x0000, 0x4000, 0x6200, 0x7200, 0xFE00, 0xFE00, 0xFE00 },
  { 0x0000, 0x0000, 0x0000, 0x0020, 0x0060, 0x0020, 0x0020, 0x0038, 0x0010, 0x0000, 0x4000, 0x6200, 0x7200, 0xFE00, 0xFE00, 0xFE00 },
  { 0x0000, 0x0000, 0x0000, 0x0020, 0x0060, 0x0020, 0x0020, 0x0038, 0x0010, 0x0000, 0x4000, 0x6200, 0x7200, 0xFE00, 0xFE00, 0xFE00 },
  { 0x0000, 0x0000, 0x0000, 0x0020, 0x0060, 0x0020, 0x0020, 0x0038, 0x0018, 0x0000, 0x4000, 0x6200, 0x7200, 0xFE00, 0xFE00, 0xFE00 },
  { 0x0000, 0x0000, 0x0000, 0x0020, 0x0060, 0x0020, 0x0020, 0x0038, 0x0050, 0x0000, 0x4000, 0x6200, 0x7200, 0xFE00, 0xFE00, 0xFE00 },
  { 0x0000, 0x0000, 0x0000, 0x0020, 0x0060, 0x0020, 0x0020, 0x0038, 0x0078, 0x0000, 0x4000, 0x6200, 0x7200, 0xFE00, 0xFE00, 0xFE00 },
  { 0x0000, 0x0000, 0x0000, 0x0000, 0x0020, 0x0020, 0x0020, 0x0038, 0x0078, 0x0000, 0x4000, 0x6200, 0x7200, 0xFE00, 0xFE00, 0xFE00 },
  { 0x0000, 0x0000, 0x0000, 0x0000, 0x0020, 0x0020, 0x0020, 0x0030, 0x0078, 0x0000, 0x4000, 0x6200, 0x7200, 0xFE00, 0xFE00, 0xFE00 },
  { 0x0000, 0x0000, 0x0000, 0x0000, 0x0060, 0x0020, 0x0020, 0x0030, 0x0078, 0x0000, 0x4000, 0x6200, 0x7200, 0xFE00, 0xFE00, 0xFE00 },
  { 0x0000, 0x0000, 0x0000, 0x0000, 0x0060, 0x0020, 0x0020, 0x0038, 0x0078, 0x0000, 0x4000, 0x6200, 0x7200, 0xFE00, 0xFE00, 0xFE00 },
  { 0x0000, 0x0000, 0x0000, 0x0000, 0x0020, 0x0020, 0x0020, 0x0030, 0x0078, 0x0000, 0x4000, 0x6200, 0x7200, 0xFE00, 0xFE00, 0xFE00 },
  { 0x0000, 0x0000, 0x0000, 0x0000, 0x0020, 0x0020, 0x0020, 0x0030, 0x0070, 0x0000, 0x4000, 0x6200, 0x7200, 0xFE00, 0xFE00, 0xFE00 },
  { 0x0000, 0x0000, 0x0000, 0x0000, 0x0020, 0x0020, 0x0020, 0x0030, 0x0078, 0x0000, 0x4000, 0x7200, 0x7200, 0xFE00, 0xFE00, 0xFE00 },
  { 0x0000, 0x0000, 0x0000, 0x0000, 0x0020, 0x0020, 0x0020, 0x0030, 0x0078, 0x0000, 0x4000, 0x7200, 0x7200, 0xFE00, 0xFE00, 0xFE00 },
  { 0x0000, 0x0000, 0x0000, 0x0000, 0x0020, 0x0020, 0x0020, 0x0030, 0x0070, 0x0010, 0x4000, 0x7200, 0x7200, 0xFE00, 0xFE00, 0xFE00 },
  { 0x0000, 0x0000, 0x0000, 0x0000, 0x0000, 0x0020, 0x0020, 0x0030, 0x0078, 0x0010, 0x4000, 0x7200, 0x7A00, 0xFE00, 0xFE00, 0xFE00 },
  { 0x0000, 0x0000, 0x0000, 0x0000, 0x0000, 0x0020, 0x0020, 0x0030, 0x0070, 0x0010, 0x4000, 0x7200, 0x7A00, 0xFE00, 0xFE00, 0xFE00 },
  { 0x0000, 0x0000, 0x0000, 0x0000, 0x0000, 0x0020, 0x0020, 0x0030, 0x0070, 0x0010, 0x4000, 0x7200, 0x7800, 0xFE00, 0xFE00, 0xFE00 },
  { 0x0000, 0x0000, 0x0000, 0x0000, 0x0000, 0x0020, 0x0020, 0x0030, 0x0030, 0x0010, 0x4000, 0x7000, 0x7800, 0xFE00, 0xFE00, 0xFE00 },
  { 0x0000, 0x0000, 0x0000, 0x0000, 0x0000, 0x0020, 0x0020, 0x0030, 0x0030, 0x0018, 0x4000, 0x7000, 0x7800, 0xFE00, 0xFE00, 0xFE00 },
  { 0x0000, 0x0000, 0x0000, 0x0000, 0x0000, 0x0020, 0x0020, 0x0030, 0x0030, 0x0010, 0x4000, 0x7000, 0x7800, 0xFE00, 0xFE00, 0xFE00 },
  { 0x0000, 0x0000, 0x0000, 0x0000, 0x0000, 0x0020, 0x0020, 0x0030, 0x0070, 0x0010, 0x4000, 0x7000, 0x7800, 0xFE00, 0xFE00, 0xFE00 },
  { 0x0000, 0x0000, 0x0000, 0x0000, 0x0000, 0x0020, 0x0020, 0x0030, 0x0070, 0x0010, 0x4000, 0x7000, 0x7800, 0xFE00, 0xFE00, 0xFE00 },
  { 0x0000, 0x0000, 0x0000, 0x0000, 0x0000, 0x0020, 0x0020, 0x0020, 0x0078, 0x0010, 0x4000, 0x7000, 0x7800, 0xFE00, 0xFE00, 0xFE00 },
  { 0x0000, 0x0000, 0x0000, 0x0000, 0x0000, 0x0020, 0x0020, 0x0020, 0x0078, 0x0010, 0x4000, 0x7000, 0x7800, 0xFE00, 0xFE00, 0xFE00 },
  { 0x0000, 0x0000, 0x0000, 0x0000, 0x0000, 0x0020, 0x0020, 0x0020, 0x0078, 0x0010, 0x4000, 0x7000, 0x7800, 0xFE00, 0xFE00, 0xFE00 },
  { 0x0000, 0x0000, 0x0000, 0x0000, 0x0000, 0x0020, 0x0020, 0x0020, 0x0078, 0x0010, 0x4000, 0x7000, 0x7800, 0xFE00, 0xFE00, 0xFE00 },
  { 0x0000, 0x0000, 0x0000, 0x0000, 0x0000, 0x0020, 0x0020, 0x0020, 0x0078, 0x0010, 0x4000, 0x7000, 0x7800, 0xFE00, 0xFE00, 0xFE00 },
  { 0x0000, 0x0000, 0x0000, 0x0000, 0x0000, 0x0020, 0x0020, 0x0030, 0x0070, 0x0010, 0x4000, 0x7000, 0x7800, 0xFE00, 0xFE00, 0xFE00 },
  { 0x0000, 0x0000, 0x0000, 0x0000, 0x0000, 0x0020, 0x0020, 0x0030, 0x0030, 0x0010, 0x4000, 0x7000, 0x7800, 0xFE00, 0xFE00, 0xFE00 },
  { 0x0000, 0x0000, 0x0000, 0x0000, 0x0000, 0x0020, 0x0060, 0x0030, 0x0030, 0x0010, 0x4000, 0x7000, 0x7800, 0xFE00, 0xFE00, 0xFE00 },
  { 0x0000, 0x0000, 0x0000, 0x0000, 0x0000, 0x0020, 0x0060, 0x0030, 0x0030, 0x0010, 0x4000, 0x7000, 0x7800, 0xFE00, 0xFE00, 0xFE00 },
  { 0x0000, 0x0000, 0x0000, 0x0000, 0x0000, 0x0020, 0x0060, 0x0030, 0x0030, 0x0010, 0x4000, 0x7100, 0x7C00, 0xFE00, 0xFE00, 0xFE00 },
  { 0x0000, 0x0000, 0x0000, 0x0000, 0x0000, 0x0020, 0x0060, 0x0030, 0x0070, 0x0010, 0x4000, 0x7100, 0x7D00, 0xFF00, 0xFF00, 0xFF00 },
  { 0x0000, 0x0000, 0x0000, 0x0000, 0x0000, 0x0020, 0x0020, 0x0030, 0x0070, 0x0010, 0x4000, 0x7100, 0x7D00, 0xFF00, 0xFF00, 0xFF00 },
  { 0x0000, 0x0000, 0x0000, 0x0000, 0x0000, 0x0020, 0x0020, 0x0030, 0x0070, 0x0010, 0x4000, 0x7100, 0x7D00, 0xFF00, 0xFF00, 0xFF00 },
  { 0x0000, 0x0000, 0x0000, 0x0000, 0x0000, 0x0020, 0x0040, 0x0030, 0x0070, 0x0000, 0x4000, 0x7100, 0x7D00, 0xFF00, 0xFF00, 0xFF00 },
  { 0x0000, 0x0000, 0x0000, 0x0000, 0x0000, 0x0020, 0x0040, 0x0030, 0x0070, 0x0000, 0x6000, 0x7100, 0x7D00, 0xFF00, 0xFF00, 0xFF00 },
  { 0x0000, 0x0000, 0x0000, 0x0000, 0x0000, 0x0020, 0x0040, 0x0030, 0x0070, 0x0000, 0x6000, 0x7100, 0x7D00, 0xFF00, 0xFF00, 0xFF00 },
  { 0x0000, 0x0000, 0x0000, 0x0000, 0x0040, 0x0020, 0x0040, 0x0030, 0x0070, 0x0000, 0x6000, 0x7100, 0x7D00, 0xFF00, 0xFF00, 0xFF00 },
  { 0x0000, 0x0000, 0x0000, 0x0000, 0x0040, 0x0020, 0x0060, 0x0030, 0x0070, 0x0000, 0x6000, 0x7100, 0x7D00, 0xFF00, 0xFF00, 0xFF00 },
  { 0x0000, 0x0000, 0x0000, 0x0000, 0x0040, 0x0020, 0x0060, 0x0030, 0x0070, 0x0000, 0x6000, 0x6100, 0x7D00, 0xFF00, 0xFF00, 0xFF00 },
  { 0x0000, 0x0000, 0x0000, 0x0000, 0x0040, 0x0020, 0x0060, 0x0030, 0x0070, 0x0000, 0x6000, 0x6100, 0x7D00, 0xFF00, 0xFF00, 0xFF00 },
  { 0x0000, 0x0000, 0x0000, 0x0000, 0x0040, 0x0060, 0x0060, 0x0030, 0x0070, 0x0000, 0x6000, 0x6100, 0x6D00, 0xFF00, 0xFF00, 0xFF00 },
  { 0x0000, 0x0000, 0x0000, 0x0000, 0x0060, 0x0020, 0x0060, 0x0070, 0x0070, 0x0000, 0x6000, 0x6100, 0x6D00, 0xFF00, 0xFF00, 0xFF00 },
  { 0x0000, 0x0000, 0x0000, 0x0000, 0x0060, 0x0020, 0x0020, 0x0070, 0x0070, 0x0000, 0x6000, 0x6100, 0x6D00, 0xFF00, 0xFF00, 0xFF00 },
  { 0x0000, 0x0000, 0x0000, 0x0000, 0x0060, 0x0020, 0x0020, 0x0070, 0x0070, 0x0000, 0x6000, 0x6100, 0x6D00, 0xFF00, 0xFF00, 0xFF00 },
  { 0x0000, 0x0000, 0x0000, 0x0000, 0x0060, 0x0020, 0x0020, 0x0070, 0x0070, 0x0000, 0x6000, 0x6100, 0x6D00, 0xFF00, 0xFF00, 0xFF00 },
  { 0x0000, 0x0000, 0x0000, 0x0000, 0x0060, 0x0020, 0x0020, 0x0070, 0x0070, 0x0000, 0x6000, 0x6100, 0x6D00, 0xFF00, 0xFF00, 0xFF00 },
  { 0x0000, 0x0000, 0x0000, 0x0000, 0x0060, 0x0040, 0x0020, 0x0070, 0x0070, 0x0000, 0x6000, 0x6100, 0x6D00, 0xFF00, 0xFF00, 0xFF00 },
  { 0x0000, 0x0000, 0x0000, 0x0000, 0x0060, 0x0040, 0x0020, 0x0070, 0x0070, 0x0000, 0x6000, 0x6100, 0x6D00, 0xFF00, 0xFF00, 0xFF00 },
  { 0x0000, 0x0000, 0x0000, 0x0000, 0x0060, 0x0020, 0x0020, 0x0070, 0x0030, 0x0000, 0x6000, 0x6100, 0x6900, 0xFF00, 0xFF00, 0xFF00 },
  { 0x0000, 0x0000, 0x0000, 0x0000, 0x0060, 0x0020, 0x0020, 0x0078, 0x0078, 0x0000, 0x4000, 0x6100, 0x6100, 0xFF00, 0xFF00, 0xFF00 },
  { 0x0000, 0x0000, 0x0000, 0x0000, 0x0060, 0x0020, 0x0020, 0x0038, 0x0078, 0x0000, 0x0000, 0x6100, 0x7100, 0xFF00, 0xFF00, 0xFF00 },
  { 0x0000, 0x0000, 0x0000, 0x0020, 0x0060, 0x0020, 0x0020, 0x0038, 0x0078, 0x0000, 0x4000, 0x6000, 0x7100, 0xFF00, 0xFF00, 0xFF00 },
  { 0x0000, 0x0000, 0x0000, 0x0020, 0x0070, 0x0020, 0x0030, 0x0038, 0x0078, 0x0008, 0x4000, 0x6000, 0xF100, 0xF100, 0xFF00, 0xFF00 },
  { 0x0000, 0x0000, 0x0000, 0x0020, 0x0030, 0x0020, 0x0030, 0x0038, 0x0078, 0x0038, 0x4000, 0x4000, 0xE000, 0xF100, 0xFF00, 0xFF00 },
  { 0x0000, 0x0000, 0x0000, 0x0020, 0x0030, 0x0020, 0x0030, 0x003C, 0x007C, 0x003C, 0x0000, 0x4000, 0xC000, 0xC100, 0xE100, 0xFF00 },
  { 0x0000, 0x0000, 0x0020, 0x0020, 0x0030, 0x0020, 0x0030, 0x003C, 0x003C, 0x003C, 0x0020, 0x4000, 0xC000, 0xC000, 0xE100, 0xFF00 },
  { 0x0000, 0x0000, 0x0020, 0x0020, 0x0030, 0x0020, 0x0030, 0x003C, 0x003C, 0x003E, 0x0020, 0x0000, 0x8000, 0xC000, 0xC100, 0xC100 },
  { 0x0000, 0x0000, 0x0000, 0x0030, 0x0030, 0x0030, 0x0038, 0x001E, 0x003E, 0x003E, 0x000C, 0x8000, 0x8000, 0x8000, 0xC000, 0xC100 },
  { 0x0000, 0x0000, 0x0010, 0x0030, 0x0030, 0x0030, 0x0018, 0x001E, 0x003E, 0x003E, 0x000F, 0x0008, 0x0000, 0x8000, 0x8000, 0xC000 },
  { 0x0000, 0x0000, 0x0010, 0x0038, 0x0038, 0x0030, 0x0018, 0x001E, 0x003F, 0x003F, 0x001F, 0x0008, 0x0000, 0x0000, 0x0000, 0x8000 },
  { 0x0000, 0x0010, 0x0010, 0x0038, 0x0018, 0x0030, 0x001C, 0x001F, 0x001F, 0x001F, 0x003F, 0x0017, 0x0000, 0x0000, 0x0000, 0x0000 },
  { 0x0000, 0x0010, 0x0010, 0x003C, 0x001C, 0x0038, 0x001C, 0x001F, 0x001F, 0x003F, 0x003F, 0x0017, 0x0015, 0x0000, 0x0000, 0x0000 },
  { 0x0000, 0x0018, 0x0018, 0x003C, 0x001C, 0x0038, 0x001C, 0x001F, 0x001F, 0x003F, 0x003F, 0x0017, 0x0017, 0x0002, 0x0000, 0x0000 },
  { 0x0000, 0x0008, 0x0018, 0x003E, 0x001C, 0x0018, 0x001A, 0x000F, 0x000F, 0x001F, 0x003F, 0x003F, 0x000D, 0x0000, 0x0000, 0x0000 },
  { 0x0008, 0x0008, 0x001C, 0x003E, 0x001E, 0x001C, 0x002F, 0x000F, 0x000F, 0x000F, 0x001F, 0x001F, 0x001B, 0x000B, 0x000A, 0x0000 },
  { 0x000C, 0x000C, 0x001F, 0x003E, 0x000E, 0x001C, 0x007D, 0x000F, 0x000F, 0x000F, 0x001F, 0x003F, 0x001F, 0x001B, 0x000B, 0x0000 },
  { 0x000C, 0x000C, 0x001F, 0x003F, 0x000F, 0x001E, 0x007E, 0x000F, 0x000F, 0x000F, 0x000F, 0x001F, 0x001F, 0x001F, 0x000D, 0x0005 },
  { 0x0006, 0x000E, 0x001F, 0x000F, 0x000F, 0x005E, 0x003E, 0x0007, 0x0007, 0x0007, 0x0007, 0x000F, 0x001F, 0x000F, 0x001F, 0x000E },
  { 0x0006, 0x000F, 0x001F, 0x0007, 0x0007, 0x004F, 0x007F, 0x0047, 0x0007, 0x0007, 0x0007, 0x0007, 0x001F, 0x001F, 0x000F, 0x000F },
  { 0x0007, 0x001F, 0x001F, 0x0007, 0x0007, 0x004F, 0x00FF, 0x0067, 0x0043, 0x0003, 0x0003, 0x0003, 0x0007, 0x001F, 0x000F, 0x000F },
  { 0x000F, 0x001F, 0x001F, 0x0003, 0x0003, 0x004F, 0x00BF, 0x003B, 0x0003, 0x0003, 0x0003, 0x0001, 0x0003, 0x0003, 0x000F, 0x0007 },
  { 0x000F, 0x001F, 0x000B, 0x0003, 0x0003, 0x0047, 0x00FF, 0x00BF, 0x0083, 0x0001, 0x0001, 0x0001, 0x0001, 0x0001, 0x0009, 0x000F },
  { 0x001F, 0x000F, 0x0001, 0x0001, 0x0001, 0x0087, 0x01EF, 0x003F, 0x00B1, 0x0081, 0x0000, 0x0000, 0x0000, 0x0000, 0x0000, 0x0004 },
  { 0x000F, 0x000F, 0x0000, 0x0000, 0x0000, 0x0083, 0x03CF, 0x027F, 0x033F, 0x0100, 0x0100, 0x0000, 0x0000, 0x0000, 0x0000, 0x0000 },
  { 0x000F, 0x000C, 0x0000, 0x0000, 0x0003, 0x0003, 0x03CF, 0x037F, 0x033F, 0x0100, 0x0100, 0x0000, 0x0000, 0x0000, 0x0000, 0x0000 },
  { 0x000F, 0x0004, 0x0000, 0x0000, 0x0003, 0x0003, 0x03CF, 0x037F, 0x013B, 0x0100, 0x0100, 0x0000, 0x0000, 0x0000, 0x0000, 0x0000 },
  { 0x000F, 0x0000, 0x0000, 0x0000, 0x0003, 0x0003, 0x03CF, 0x077F, 0x013B, 0x0000, 0x0000, 0x0000, 0x0000, 0x0000, 0x0000, 0x0000 },
  { 0x000F, 0x0000, 0x0000, 0x0000, 0x0003, 0x0003, 0x03CF, 0x077F, 0x013B, 0x0000, 0x0000, 0x0000, 0x0000, 0x0000, 0x0000, 0x0000 },
  { 0x000F, 0x0000, 0x0000, 0x0000, 0x0003, 0x0083, 0x03EF, 0x037F, 0x013F, 0x0000, 0x0000, 0x0000, 0x0000, 0x0000, 0x0000, 0x0000 },
  { 0x0007, 0x0000, 0x0000, 0x0000, 0x0001, 0x0083, 0x03E7, 0x037F, 0x003F, 0x0100, 0x0000, 0x0000, 0x0000, 0x0000, 0x0000, 0x0000 },
  { 0x0007, 0x0000, 0x0000, 0x0000, 0x0001, 0x0083, 0x03E7, 0x027F, 0x023F, 0x0100, 0x0100, 0x0100, 0x0000, 0x0000, 0x0000, 0x0000 },
  { 0x0007, 0x0000, 0x0000, 0x0000, 0x0001, 0x0083, 0x03E7, 0x027F, 0x023F, 0x0110, 0x0100, 0x0100, 0x0000, 0x0000, 0x0000, 0x0000 },
  { 0x0006, 0x0000, 0x0000, 0x0000, 0x0001, 0x0083, 0x01E7, 0x027F, 0x033F, 0x0110, 0x0100, 0x0100, 0x0000, 0x0000, 0x0000, 0x0000 },
  { 0x0006, 0x0000, 0x0000, 0x0000, 0x0001, 0x0081, 0x01E7, 0x03FF, 0x023F, 0x0118, 0x0100, 0x0100, 0x0000, 0x0000, 0x0000, 0x0000 },
  { 0x0002, 0x0000, 0x0000, 0x0000, 0x0001, 0x0081, 0x01E3, 0x03FF, 0x023F, 0x0118, 0x0100, 0x0100, 0x0000, 0x0000, 0x0000, 0x0000 },
  { 0x0000, 0x0000, 0x0000, 0x0000, 0x0001, 0x00C1, 0x01E3, 0x03BF, 0x023F, 0x011C, 0x0100, 0x0100, 0x0000, 0x0000, 0x0000, 0x0000 },
  { 0x0001, 0x0000, 0x0000, 0x0000, 0x0000, 0x00C1, 0x01E3, 0x01B7, 0x02BF, 0x019C, 0x0000, 0x0080, 0x0000, 0x0000, 0x0000, 0x0000 },
  { 0x0000, 0x0000, 0x0000, 0x0000, 0x0000, 0x00C1, 0x01E3, 0x013F, 0x02BF, 0x019C, 0x0080, 0x0080, 0x0000, 0x0000, 0x0000, 0x0000 },
  { 0x0000, 0x0000, 0x0000, 0x0000, 0x0000, 0x00C1, 0x01F3, 0x013F, 0x029F, 0x019C, 0x0080, 0x0080, 0x0000, 0x0000, 0x0000, 0x0000 },
  { 0x0000, 0x0000, 0x0000, 0x0000, 0x0000, 0x00C1, 0x01F3, 0x013F, 0x029F, 0x019C, 0x0080, 0x0080, 0x0000, 0x0000, 0x0000, 0x0000 },
  { 0x0000, 0x0000, 0x0000, 0x0000, 0x0000, 0x00C1, 0x01F3, 0x033F, 0x029F, 0x008C, 0x0080, 0x0080, 0x0000, 0x0000, 0x0000, 0x0000 },
  { 0x0000, 0x0000, 0x0000, 0x0000, 0x0000, 0x00C0, 0x01F3, 0x033F, 0x029F, 0x008C, 0x0080, 0x0080, 0x0000, 0x0000, 0x0000, 0x0000 },
  { 0x0000, 0x0000, 0x0000, 0x0000, 0x0000, 0x00C0, 0x01FB, 0x03BF, 0x029F, 0x008C, 0x0080, 0x0080, 0x0000, 0x0000, 0x0000, 0x0000 },
  { 0x0000, 0x0000, 0x0000, 0x0000, 0x0000, 0x00E0, 0x03FB, 0x03BF, 0x001F, 0x018C, 0x0080, 0x0080, 0x0000, 0x0000, 0x0000, 0x0000 },
  { 0x0000, 0x0000, 0x0000, 0x0000, 0x0000, 0x01E0, 0x03FB, 0x02BF, 0x029F, 0x018C, 0x0080, 0x0080, 0x0000, 0x0000, 0x0000, 0x0000 },
  { 0x0000, 0x0000, 0x0000, 0x0000, 0x0000, 0x03E0, 0x02FF, 0x023F, 0x021F, 0x0184, 0x0180, 0x0080, 0x0080, 0x0000, 0x0000, 0x0000 },
  { 0x0000, 0x0000, 0x0000, 0x0000, 0x0000, 0x03F0, 0x06FF, 0x041F, 0x000F, 0x0104, 0x0100, 0x0100, 0x0080, 0x0000, 0x0000, 0x0000 },
  { 0x0000, 0x0000, 0x0000, 0x0000, 0x0000, 0x03F0, 0x06BF, 0x001F, 0x000F, 0x0000, 0x0000, 0x0100, 0x0100, 0x0180, 0x0000, 0x0000 },
  { 0x0000, 0x0000, 0x0000, 0x0000, 0x00C0, 0x07F8, 0x04BF, 0x001F, 0x000F, 0x0000, 0x0000, 0x0100, 0x0100, 0x0100, 0x0180, 0x0000 },
  { 0x0000, 0x0000, 0x0000, 0x0000, 0x03C0, 0x07F8, 0x00BF, 0x001F, 0x000F, 0x0000, 0x0000, 0x0000, 0x0100, 0x0100, 0x0100, 0x0100 },
  { 0x0000, 0x0000, 0x0000, 0x03E0, 0x07FD, 0x00BF, 0x001F, 0x0007, 0x0000, 0x0000, 0x0000, 0x0100, 0x0300, 0x0100, 0x0100, 0x0100 },
  { 0x0000, 0x0000, 0x03F8, 0x06FF, 0x009F, 0x000F, 0x0002, 0x0000, 0x0000, 0x0000, 0x0000, 0x0200, 0x0200, 0x0100, 0x0100, 0x0000 },
  { 0x0000, 0x03FF, 0x06FF, 0x009F, 0x0007, 0x0000, 0x0000, 0x0000, 0x0000, 0x0000, 0x0000, 0x0200, 0x0200, 0x0100, 0x0000, 0x0000 },
  { 0x07FF, 0x06FF, 0x008F, 0x0000, 0x0000, 0x0000, 0x0000, 0x0000, 0x0000, 0x0000, 0x0200, 0x0200, 0x0200, 0x0100, 0x0000, 0x0000 },
  { 0x0086, 0x0000, 0x0000, 0x0000, 0x0000, 0x0000, 0x0000, 0x0000, 0x0000, 0x0000, 0x0600, 0x0200, 0x0300, 0x0000, 0x0000, 0x0000 },
  { 0x0000, 0x0000, 0x0000, 0x0000, 0x0000, 0x0000, 0x0000, 0x0000, 0x0000, 0x0400, 0x0600, 0x0300, 0x0000, 0x0000, 0x0000, 0x0000 },
  { 0x0000, 0x0000, 0x0000, 0x0000, 0x0000, 0x0000, 0x0000, 0x0000, 0x0000, 0x0600, 0x0200, 0x0100, 0x0000, 0x0000, 0x0000, 0x0000 },
  { 0x0000, 0x0000, 0x0000, 0x0000, 0x0000, 0x0000, 0x0000, 0x0000, 0x0400, 0x0600, 0x0300, 0x0000, 0x0000, 0x0000, 0x0000, 0x0000 },
  { 0x0000, 0x0000, 0x0000, 0x0000, 0x0000, 0x0000, 0x0000, 0x0000, 0x0400, 0x0700, 0x0100, 0x0000, 0x0000, 0x0000, 0x0000, 0x0000 },
  { 0x0000, 0x0000, 0x0000, 0x0000, 0x0000, 0x0000, 0x0000, 0x0000, 0x0700, 0x0500, 0x0000, 0x0000, 0x0000, 0x0000, 0x0000, 0x0000 },
  { 0x0000, 0x0000, 0x0000, 0x0000, 0x0000, 0x0000, 0x0000, 0x0200, 0x0700, 0x0400, 0x0000, 0x0000, 0x0000, 0x0000, 0x0000, 0x0000 },
  { 0x0000, 0x0000, 0x0000, 0x0000, 0x0000, 0x0000, 0x0200, 0x0300, 0x0600, 0x0400, 0x0000, 0x0000, 0x0000, 0x0000, 0x0000, 0x0000 },
  { 0x0000, 0x0000, 0x0000, 0x0000, 0x0000, 0x0000, 0x0200, 0x0200, 0x0400, 0x0400, 0x0000, 0x0000, 0x0000, 0x0000, 0x0000, 0x0000 },
  { 0x0000, 0x0000, 0x0000, 0x0000, 0x0000, 0x0000, 0x0200, 0x0200, 0x0600, 0x0000, 0x0000, 0x0000, 0x0000, 0x0000, 0x0000, 0x0000 },
  { 0x0000, 0x0000, 0x0000, 0x0000, 0x0000, 0x0600, 0x0200, 0x0200, 0x0200, 0x0000, 0x0000, 0x0000, 0x0000, 0x0000, 0x0000, 0x0000 },
  { 0x0000, 0x0000, 0x0000, 0x0000, 0x0000, 0x0600, 0x0200, 0x0200, 0x0200, 0x0000, 0x0000, 0x0000, 0x0000, 0x0000, 0x0000, 0x0000 },
  { 0x0000, 0x0000, 0x0000, 0x0000, 0x0200, 0x0600, 0x0200, 0x0300, 0x0000, 0x0000, 0x0000, 0x0000, 0x0000, 0x0000, 0x0000, 0x0000 },
  { 0x0000, 0x0000, 0x0000, 0x0000, 0x0200, 0x0600, 0x0200, 0x0300, 0x0000, 0x0000, 0x0000, 0x0000, 0x0000, 0x0000, 0x0000, 0x0000 },
  { 0x0000, 0x0000, 0x0000, 0x0000, 0x0200, 0x0600, 0x0100, 0x0100, 0x0000, 0x0000, 0x0000, 0x0000, 0x0000, 0x0000, 0x0000, 0x0000 },
  { 0x0000, 0x0000, 0x0000, 0x0000, 0x0200, 0x0700, 0x0100, 0x0000, 0x0000, 0x0000, 0x0000, 0x0000, 0x0000, 0x0000, 0x0000, 0x0000 },
  { 0x0000, 0x0000, 0x0000, 0x0000, 0x0200, 0x0780, 0x0000, 0x0000, 0x0000, 0x0000, 0x0000, 0x0000, 0x0000, 0x0000, 0x0000, 0x0000 },
  { 0x0000, 0x0000, 0x0000, 0x0000, 0x0380, 0x0300, 0x0000, 0x0000, 0x0000, 0x0000, 0x0000, 0x0000, 0x0000, 0x0000, 0x0000, 0x0000 },
  { 0x0000, 0x0000, 0x0000, 0x0000, 0x0380, 0x0200, 0x0000, 0x0000, 0x0000, 0x0000, 0x0000, 0x0000, 0x0000, 0x0000, 0x8000, 0xC000 },
  { 0x0000, 0x0000, 0x0000, 0x0180, 0x0100, 0x0200, 0x0000, 0x0000, 0x8000, 0xC000, 0xE000, 0xF800, 0xFC00, 0xFE00, 0xFF00, 0xFFC0 },
  { 0x0000, 0x0000, 0x8000, 0xC180, 0xE100, 0xFA00, 0xFC00, 0xFE00, 0xFF00, 0xFFC0, 0xFFE0, 0xFFF0, 0xFFFC, 0xFFFE, 0xFFFF, 0xFFFF },
  { 0xFC00, 0xFE00, 0xFE00, 0xFEC0, 0xFEE0, 0xFEF0, 0xFFFC, 0xFFFE, 0xFFFF, 0xFFFF, 0xFFFF, 0xFFFF, 0xFFFF, 0xFFFF, 0xFFFF, 0xFFFF },
  { 0xFFF8, 0xFE7E, 0xFE7F, 0xFEFF, 0xFEFF, 0xFFFF, 0xFFFF, 0xFFFF, 0xFFFF, 0xFFFF, 0xFFFF, 0xFFFF, 0xFFFF, 0xFFFF, 0xFFFF, 0xFFFF },
  { 0xFFFF, 0xFE7F, 0xFE7F, 0xFE7F, 0xFF7F, 0xFFFF, 0xFFFF, 0xFFFF, 0xFFFF, 0xFFFF, 0xFFFF, 0xFFFF, 0xFFFF, 0xFFFF, 0xFFFF, 0xFFFF },
  { 0xFFFF, 0xFE7F, 0xFE7F, 0xFF7F, 0xFF7F, 0xFFFF, 0xFFFF, 0xFFFF, 0xFFFF, 0xFFFF, 0xFFFF, 0xFFFF, 0xFFFF, 0xFFFF, 0xFFFF, 0xFFFF },
  { 0xFFFF, 0xFE7F, 0xFE7F, 0xFF3F, 0xFFFF, 0xFFFF, 0xFFFF, 0xFFFF, 0xFFFF, 0xFFFF, 0xFFFF, 0xFFFF, 0xFFFF, 0xFFFF, 0xFFFF, 0xFFFF },
  { 0xFFFF, 0xFE7F, 0xFE3F, 0xFFBF, 0xFFBF, 0xFFFF, 0xFFFF, 0xFFFF, 0xFFFF, 0xFFFF, 0xFFFF, 0xFFFF, 0xFFFF, 0xFFFF, 0xFFFF, 0xFFFF },
  { 0xFFFF, 0xFE1F, 0xFE3F, 0xFFFF, 0xFFFF, 0xFFFF, 0xFFFF, 0xFFFF, 0xFFFF, 0xFFFF, 0xFFFF, 0xFFFF, 0xFFFF, 0xFFFF, 0xFFFF, 0xFFFF },
  { 0xFFDF, 0xFE1F, 0xFE1F, 0xFFFF, 0xFFFF, 0xFFFF, 0xFFFF, 0xFFFF, 0xFFFF, 0xFFFF, 0xFFFF, 0xFFFF, 0xFFFF, 0xFFFF, 0xFFFF, 0xFFFF },
  { 0xFF9F, 0xFF1F, 0xFF7F, 0xFF7F, 0xFFFF, 0xFFFF, 0xFFFF, 0xFFFF, 0xFFFF, 0xFFFF, 0xFFFF, 0xFFFF, 0xFFFF, 0xFFFF, 0xFFFF, 0xFFFF },
  { 0xFF9F, 0xFF3F, 0xFF7F, 0xFFFF, 0xFFFF, 0xFFFF, 0xFFFF, 0xFFFF, 0xFFFF, 0xFFFF, 0xFFFF, 0xFFFF, 0xFFFF, 0xFFFF, 0xFFFF, 0xFFFF },
  { 0xFF9F, 0xFFBF, 0xFF3F, 0xFF3F, 0xFFFF, 0xFFFF, 0xFFFF, 0xFFFF, 0xFFFF, 0xFFFF, 0xFFFF, 0xFFFF, 0xFFFF, 0xFFFF, 0xFFFF, 0xFFFF },
  { 0xFF9F, 0xFFBF, 0xFF3F, 0xFFBF, 0xFFFF, 0xFFFF, 0xFFFF, 0xFFFF, 0xFFFF, 0xFFFF, 0xFFFF, 0xFFFF, 0xFFFF, 0xFFFF, 0xFFFF, 0xFFFF },
  { 0xFFDF, 0xFF9F, 0xFF9F, 0xFFFF, 0xFFFF, 0xFFFF, 0xFFFF, 0xFFFF, 0xFFFF, 0xFFFF, 0xFFFF, 0xFFFF, 0xFFFF, 0xFFFF, 0xFFFF, 0xFFFF },
  { 0xFFDF, 0xFFCF, 0xFFDF, 0xFFFF, 0xFFFF, 0xFFFF, 0xFFFF, 0xFFFF, 0xFFFF, 0xFFFF, 0xFFFF, 0xFFFF, 0xFFFF, 0xFFFF, 0xFFFF, 0xFFFF },
  { 0xFFCF, 0xFFCF, 0xFFFF, 0xFFFF, 0xFFFF, 0xFFFF, 0xFFFF, 0xFFFF, 0xFFFF, 0xFFFF, 0xFFFF, 0xFFFF, 0xFFFF, 0xFFFF, 0xFFFF, 0xFFFF },
  { 0xFFC7, 0xFFE7, 0xFFFF, 0xFFFF, 0xFFFF, 0xFFFF, 0xFFFF, 0xFFFF, 0xFFFF, 0xFFFF, 0xFFFF, 0xFFFF, 0xFFFF, 0xFFFF, 0xFFFF, 0xFFFF },
  { 0xFF07, 0xFFFF, 0xFFFF, 0xFFFF, 0xFFFF, 0xFFFF, 0xFFFF, 0xFFFF, 0xFFFF, 0xFFFF, 0xFFFF, 0xFFFF, 0xFFFF, 0xFFFF, 0xFFFF, 0xFFFF },
  { 0xFF0F, 0xFFBF, 0xFFFF, 0xFFFF, 0xFFFF, 0xFFFF, 0xFFFF, 0xFFFF, 0xFFFF, 0xFFFF, 0xFFFF, 0xFFFF, 0xFFFF, 0xFFFF, 0xFFFF, 0xFFFF },
  { 0xFF9F, 0xFF9F, 0xFFFF, 0xFFFF, 0xFFFF, 0xFFFF, 0xFFFF, 0xFFFF, 0xFFFF, 0xFFFF, 0xFFFF, 0xFFFF, 0xFFFF, 0xFFFF, 0xFFFF, 0xFFFF },
  { 0xFFCF, 0xFF9F, 0xFFDF, 0xFFFF, 0xFFFF, 0xFFFF, 0xFFFF, 0xFFFF, 0xFFFF, 0xFFFF, 0xFFFF, 0xFFFF, 0xFFFF, 0xFFFF, 0xFFFF, 0xFFFF },
  { 0xFFCF, 0xFFCF, 0xFFCF, 0xFFDF, 0xFFFF, 0xFFFF, 0xFFFF, 0xFFFF, 0xFFFF, 0xFFFF, 0xFFFF, 0xFFFF, 0xFFFF, 0xFFFF, 0xFFFF, 0xFFFF },
  { 0xFFCF, 0xFFCF, 0xFFE7, 0xFFE7, 0xFFEF, 0xFFFF, 0xFFFF, 0xFFFF, 0xFFFF, 0xFFFF, 0xFFFF, 0xFFFF, 0xFFFF, 0xFFFF, 0xFFFF, 0xFFFF },
  { 0xFF9F, 0xFF8F, 0xFF8F, 0xFFC3, 0xFFE3, 0xFFF7, 0xFFF7, 0xFFFF, 0xFFFF, 0xFFFF, 0xFFFF, 0xFFFF, 0xFFFF, 0xFFFF, 0xFFFF, 0xFFFF },
  { 0xFFFF, 0xFFFF, 0xFFFF, 0xFF9F, 0xFF03, 0xFF03, 0xFF03, 0xFF83, 0xFFFB, 0xFFFF, 0xFFFF, 0xFFFF, 0xFFFF, 0xFFFF, 0xFFFF, 0xFFFF },
  { 0xFFFF, 0xFFFF, 0xFFFF, 0xFFFF, 0xFFFF, 0xFFFF, 0xFFFB, 0xFFF3, 0xFF03, 0xFF03, 0xFF03, 0xFF0B, 0xFFBF, 0xFFFF, 0xFFFF, 0xFFFF },
  { 0xFFFF, 0xFFFF, 0xFFFF, 0xFFFF, 0xFFFF, 0xFFFF, 0xFFFF, 0xFFFF, 0xFFFF, 0xFFEF, 0xFFE7, 0xFFE3, 0xFFC3, 0xFF83, 0xFF0F, 0xFF1F },
  { 0xFFFF, 0xFFFF, 0xFFFF, 0xFFFF, 0xFFFF, 0xFFFF, 0xFFFF, 0xFFFF, 0xFFC7, 0xFFC7, 0xFFC7, 0xFFCF, 0xFFCF, 0xFF8F, 0xFF9F, 0xFF9F },
  { 0xFFFF, 0xFFFF, 0xFFFF, 0xFFFF, 0xFFFF, 0xFFFF, 0xFF8F, 0xFF87, 0xFFCF, 0xFFCF, 0xFFCF, 0xFFCF, 0xFF8F, 0xFF8F, 0xFFDF, 0xFFFF },
  { 0xFFFF, 0xFFFF, 0xFFFF, 0xFFFF, 0xFFFF, 0xFF0F, 0xFF1F, 0xFF9F, 0xFF9F, 0xFFCF, 0xFFCF, 0xFF8F, 0xFFCF, 0xFFEF, 0xFFFF, 0xFFFF },
  { 0xFFFF, 0xFFFF, 0xFFFF, 0xFFBF, 0xFF3F, 0xFE3F, 0xFF3F, 0xFF9F, 0xFF9F, 0xFF8F, 0xFFCF, 0xFFCF, 0xFFFF, 0xFFFF, 0xFFFF, 0xFFFF },
  { 0xFFFF, 0xFFFF, 0xFFFF, 0xFF7F, 0xFE7F, 0xFC7F, 0xFC3F, 0xFF1F, 0xFF8F, 0xFF8F, 0xFFDF, 0xFFFF, 0xFFFF, 0xFFFF, 0xFFFF, 0xFFFF },
  { 0xFFFF, 0xFFFF, 0xFFFF, 0xFFFF, 0xFCFF, 0xFC7F, 0xFC3F, 0xF80F, 0xFF0F, 0xFF9F, 0xFFFF, 0xFFFF, 0xFFFF, 0xFFFF, 0xFFFF, 0xFFFF },
  { 0xFFFF, 0xFFFF, 0xFFFF, 0xFFFF, 0xFDFF, 0xFCFF, 0xF81F, 0xF80F, 0xFB8F, 0xFFDF, 0xFFFF, 0xFFFF, 0xFFFF, 0xFFFF, 0xFFFF, 0xFFFF },
  { 0xFFFF, 0xFFFF, 0xFFFF, 0xFFFF, 0xFFFF, 0xFCDF, 0xF81F, 0xF80F, 0xFB9F, 0xFFFF, 0xFFFF, 0xFFFF, 0xFFFF, 0xFFFF, 0xFFFF, 0xFFFF },
};

matrixLED_HandleTypeDef hmatrix = {
    .gpio = {
        {GPIOF, 0},
        {GPIOF, 1},
        {GPIOA, 15},
        {GPIOA, 14},
        {GPIOA, 13},
        {GPIOA, 12},
        {GPIOA, 11},
        {GPIOA, 8},
        {GPIOA, 0},
        {GPIOA, 1},
        {GPIOA, 2},
        {GPIOA, 3},
        {GPIOA, 4},
        {GPIOA, 5},
        {GPIOA, 6},
        {GPIOA, 7}
    }
};

volatile uint32_t i = 0;
/* USER CODE END PM */

TIM_HandleTypeDef htim1;
TIM_HandleTypeDef htim3;
DMA_HandleTypeDef hdma_tim1_ch1;
DMA_HandleTypeDef hdma_tim1_ch2;
DMA_HandleTypeDef hdma_tim1_ch4_trig_com;
DMA_HandleTypeDef hdma_tim1_ch3_up;

UART_HandleTypeDef huart1;

/* USER CODE BEGIN PV */

void uart_print(char* str) {
    HAL_UART_Transmit(&huart1, (uint8_t*)str, strlen(str), HAL_MAX_DELAY);
}
/* USER CODE END PV */

void SystemClock_Config(void);
static void MX_GPIO_Init(void);
static void MX_DMA_Init(void);
static void MX_TIM1_Init(void);
static void MX_TIM3_Init(void);
static void MX_USART1_UART_Init(void);

int main(void)
{

  /* MCU Configuration--------------------------------------------------------*/

  /* Reset of all peripherals, Initializes the Flash interface and the Systick. */
  HAL_Init();

  /* Configure the system clock */
  SystemClock_Config();

  /* Initialize all configured peripherals */
  MX_GPIO_Init();
  MX_DMA_Init();
  MX_TIM1_Init();
  MX_TIM3_Init();
  MX_USART1_UART_Init();
  /* USER CODE BEGIN 2 */
  HAL_TIM_Base_Start_IT(&htim1);
  HAL_TIM_Base_Start_IT(&htim3);
  matrixLED_init();
  matrixLED_update(&hmatrix, led_animation[i]);
  HAL_DMA_Start(&hdma_tim1_ch1, (uint32_t)gpiof_moder, (uint32_t)&GPIOF->MODER, 16);
  __HAL_TIM_ENABLE_DMA(&htim1, TIM_DMA_CC1);

  HAL_DMA_Start(&hdma_tim1_ch2, (uint32_t)gpioa_moder, (uint32_t)&GPIOA->MODER, 16);
  __HAL_TIM_ENABLE_DMA(&htim1, TIM_DMA_CC2);

  HAL_DMA_Start(&hdma_tim1_ch4_trig_com, (uint32_t)gpiof_odr, (uint32_t)&GPIOF->ODR, 16);
  __HAL_TIM_ENABLE_DMA(&htim1, TIM_DMA_CC4);

  HAL_DMA_Start(&hdma_tim1_ch3_up, (uint32_t)gpioa_odr, (uint32_t)&GPIOA->ODR, 16);
  __HAL_TIM_ENABLE_DMA(&htim1, TIM_DMA_CC3);
  //i = (i + 1) % NUM_FRAMES;
  /* USER CODE END 2 */

  /* Infinite loop */
  while (1)
  {

    /* USER CODE BEGIN 3 */
    for (uint32_t i = 0; i < NUM_FRAMES; i++){
      matrixLED_update(&hmatrix, led_animation[i]);
      HAL_Delay(40);
    }
    HAL_Delay(1000);
  }
  /* USER CODE END 3 */
}

void SystemClock_Config(void)
{
  RCC_OscInitTypeDef RCC_OscInitStruct = {0};
  RCC_ClkInitTypeDef RCC_ClkInitStruct = {0};
  RCC_PeriphCLKInitTypeDef PeriphClkInit = {0};

  /** Initializes the RCC Oscillators according to the specified parameters
  * in the RCC_OscInitTypeDef structure.
  */
  RCC_OscInitStruct.OscillatorType = RCC_OSCILLATORTYPE_HSI;
  RCC_OscInitStruct.HSIState = RCC_HSI_ON;
  RCC_OscInitStruct.HSICalibrationValue = RCC_HSICALIBRATION_DEFAULT;
  RCC_OscInitStruct.PLL.PLLState = RCC_PLL_ON;
  RCC_OscInitStruct.PLL.PLLSource = RCC_PLLSOURCE_HSI;
  RCC_OscInitStruct.PLL.PLLMUL = RCC_PLL_MUL12;
  RCC_OscInitStruct.PLL.PREDIV = RCC_PREDIV_DIV1;
  if (HAL_RCC_OscConfig(&RCC_OscInitStruct) != HAL_OK)
  {
    Error_Handler();
  }

  /** Initializes the CPU, AHB and APB buses clocks
  */
  RCC_ClkInitStruct.ClockType = RCC_CLOCKTYPE_HCLK|RCC_CLOCKTYPE_SYSCLK
                              |RCC_CLOCKTYPE_PCLK1;
  RCC_ClkInitStruct.SYSCLKSource = RCC_SYSCLKSOURCE_PLLCLK;
  RCC_ClkInitStruct.AHBCLKDivider = RCC_SYSCLK_DIV1;
  RCC_ClkInitStruct.APB1CLKDivider = RCC_HCLK_DIV1;

  if (HAL_RCC_ClockConfig(&RCC_ClkInitStruct, FLASH_LATENCY_1) != HAL_OK)
  {
    Error_Handler();
  }
  PeriphClkInit.PeriphClockSelection = RCC_PERIPHCLK_USART1;
  PeriphClkInit.Usart1ClockSelection = RCC_USART1CLKSOURCE_PCLK1;
  if (HAL_RCCEx_PeriphCLKConfig(&PeriphClkInit) != HAL_OK)
  {
    Error_Handler();
  }
}

static void MX_TIM1_Init(void)
{

  TIM_ClockConfigTypeDef sClockSourceConfig = {0};
  TIM_MasterConfigTypeDef sMasterConfig = {0};
  TIM_OC_InitTypeDef sConfigOC = {0};
  TIM_BreakDeadTimeConfigTypeDef sBreakDeadTimeConfig = {0};

  htim1.Instance = TIM1;
  htim1.Init.Prescaler = 0;
  htim1.Init.CounterMode = TIM_COUNTERMODE_UP;
  htim1.Init.Period = 999;
  htim1.Init.ClockDivision = TIM_CLOCKDIVISION_DIV1;
  htim1.Init.RepetitionCounter = 0;
  htim1.Init.AutoReloadPreload = TIM_AUTORELOAD_PRELOAD_DISABLE;
  if (HAL_TIM_Base_Init(&htim1) != HAL_OK)
  {
    Error_Handler();
  }
  sClockSourceConfig.ClockSource = TIM_CLOCKSOURCE_INTERNAL;
  if (HAL_TIM_ConfigClockSource(&htim1, &sClockSourceConfig) != HAL_OK)
  {
    Error_Handler();
  }
  if (HAL_TIM_OC_Init(&htim1) != HAL_OK)
  {
    Error_Handler();
  }
  sMasterConfig.MasterOutputTrigger = TIM_TRGO_RESET;
  sMasterConfig.MasterSlaveMode = TIM_MASTERSLAVEMODE_DISABLE;
  if (HAL_TIMEx_MasterConfigSynchronization(&htim1, &sMasterConfig) != HAL_OK)
  {
    Error_Handler();
  }
  sConfigOC.OCMode = TIM_OCMODE_TIMING;
  sConfigOC.Pulse = 0;
  sConfigOC.OCPolarity = TIM_OCPOLARITY_HIGH;
  sConfigOC.OCNPolarity = TIM_OCNPOLARITY_HIGH;
  sConfigOC.OCFastMode = TIM_OCFAST_DISABLE;
  sConfigOC.OCIdleState = TIM_OCIDLESTATE_RESET;
  sConfigOC.OCNIdleState = TIM_OCNIDLESTATE_RESET;
  if (HAL_TIM_OC_ConfigChannel(&htim1, &sConfigOC, TIM_CHANNEL_1) != HAL_OK)
  {
    Error_Handler();
  }
  if (HAL_TIM_OC_ConfigChannel(&htim1, &sConfigOC, TIM_CHANNEL_2) != HAL_OK)
  {
    Error_Handler();
  }
  if (HAL_TIM_OC_ConfigChannel(&htim1, &sConfigOC, TIM_CHANNEL_3) != HAL_OK)
  {
    Error_Handler();
  }
  if (HAL_TIM_OC_ConfigChannel(&htim1, &sConfigOC, TIM_CHANNEL_4) != HAL_OK)
  {
    Error_Handler();
  }
  sBreakDeadTimeConfig.OffStateRunMode = TIM_OSSR_DISABLE;
  sBreakDeadTimeConfig.OffStateIDLEMode = TIM_OSSI_DISABLE;
  sBreakDeadTimeConfig.LockLevel = TIM_LOCKLEVEL_OFF;
  sBreakDeadTimeConfig.DeadTime = 0;
  sBreakDeadTimeConfig.BreakState = TIM_BREAK_DISABLE;
  sBreakDeadTimeConfig.BreakPolarity = TIM_BREAKPOLARITY_HIGH;
  sBreakDeadTimeConfig.AutomaticOutput = TIM_AUTOMATICOUTPUT_DISABLE;
  if (HAL_TIMEx_ConfigBreakDeadTime(&htim1, &sBreakDeadTimeConfig) != HAL_OK)
  {
    Error_Handler();
  }

}

static void MX_TIM3_Init(void)
{

  TIM_ClockConfigTypeDef sClockSourceConfig = {0};
  TIM_MasterConfigTypeDef sMasterConfig = {0};

  htim3.Instance = TIM3;
  htim3.Init.Prescaler = 0;
  htim3.Init.CounterMode = TIM_COUNTERMODE_UP;
  htim3.Init.Period = 19999;
  htim3.Init.ClockDivision = TIM_CLOCKDIVISION_DIV1;
  htim3.Init.AutoReloadPreload = TIM_AUTORELOAD_PRELOAD_DISABLE;
  if (HAL_TIM_Base_Init(&htim3) != HAL_OK)
  {
    Error_Handler();
  }
  sClockSourceConfig.ClockSource = TIM_CLOCKSOURCE_INTERNAL;
  if (HAL_TIM_ConfigClockSource(&htim3, &sClockSourceConfig) != HAL_OK)
  {
    Error_Handler();
  }
  sMasterConfig.MasterOutputTrigger = TIM_TRGO_RESET;
  sMasterConfig.MasterSlaveMode = TIM_MASTERSLAVEMODE_DISABLE;
  if (HAL_TIMEx_MasterConfigSynchronization(&htim3, &sMasterConfig) != HAL_OK)
  {
    Error_Handler();
  }

}

static void MX_USART1_UART_Init(void)
{

  huart1.Instance = USART1;
  huart1.Init.BaudRate = 115200;
  huart1.Init.WordLength = UART_WORDLENGTH_8B;
  huart1.Init.StopBits = UART_STOPBITS_1;
  huart1.Init.Parity = UART_PARITY_NONE;
  huart1.Init.Mode = UART_MODE_TX_RX;
  huart1.Init.HwFlowCtl = UART_HWCONTROL_NONE;
  huart1.Init.OverSampling = UART_OVERSAMPLING_16;
  huart1.Init.OneBitSampling = UART_ONE_BIT_SAMPLE_DISABLE;
  huart1.AdvancedInit.AdvFeatureInit = UART_ADVFEATURE_NO_INIT;
  if (HAL_UART_Init(&huart1) != HAL_OK)
  {
    Error_Handler();
  }

}

static void MX_DMA_Init(void)
{

  /* DMA controller clock enable */
  __HAL_RCC_DMA1_CLK_ENABLE();

  /* DMA interrupt init */
  /* DMA1_Channel2_3_IRQn interrupt configuration */
  HAL_NVIC_SetPriority(DMA1_Channel2_3_IRQn, 0, 0);
  HAL_NVIC_EnableIRQ(DMA1_Channel2_3_IRQn);
  /* DMA1_Channel4_5_IRQn interrupt configuration */
  HAL_NVIC_SetPriority(DMA1_Channel4_5_IRQn, 0, 0);
  HAL_NVIC_EnableIRQ(DMA1_Channel4_5_IRQn);

}

static void MX_GPIO_Init(void)
{
  GPIO_InitTypeDef GPIO_InitStruct = {0};

  /* GPIO Ports Clock Enable */
  __HAL_RCC_GPIOF_CLK_ENABLE();
  __HAL_RCC_GPIOA_CLK_ENABLE();
  __HAL_RCC_GPIOB_CLK_ENABLE();

  /*Configure GPIO pin Output Level */
  HAL_GPIO_WritePin(GPIOF, GPIO_PIN_0|GPIO_PIN_1, GPIO_PIN_RESET);

  /*Configure GPIO pin Output Level */
  HAL_GPIO_WritePin(GPIOA, GPIO_PIN_0|GPIO_PIN_1|GPIO_PIN_2|GPIO_PIN_3
                          |GPIO_PIN_4|GPIO_PIN_5|GPIO_PIN_6|GPIO_PIN_7
                          |GPIO_PIN_8|GPIO_PIN_11|GPIO_PIN_12|GPIO_PIN_13
                          |GPIO_PIN_14|GPIO_PIN_15, GPIO_PIN_RESET);

  /*Configure GPIO pin Output Level */
  HAL_GPIO_WritePin(GPIOB, GPIO_PIN_0, GPIO_PIN_RESET);

  /*Configure GPIO pins : PF0 PF1 */
  GPIO_InitStruct.Pin = GPIO_PIN_0|GPIO_PIN_1;
  GPIO_InitStruct.Mode = GPIO_MODE_OUTPUT_PP;
  GPIO_InitStruct.Pull = GPIO_NOPULL;
  GPIO_InitStruct.Speed = GPIO_SPEED_FREQ_HIGH;
  HAL_GPIO_Init(GPIOF, &GPIO_InitStruct);

  /*Configure GPIO pins : PA0 PA1 PA2 PA3
                           PA4 PA5 PA6 PA7
                           PA8 PA11 PA12 PA13
                           PA14 PA15 */
  GPIO_InitStruct.Pin = GPIO_PIN_0|GPIO_PIN_1|GPIO_PIN_2|GPIO_PIN_3
                          |GPIO_PIN_4|GPIO_PIN_5|GPIO_PIN_6|GPIO_PIN_7
                          |GPIO_PIN_8|GPIO_PIN_11|GPIO_PIN_12|GPIO_PIN_13
                          |GPIO_PIN_14|GPIO_PIN_15;
  GPIO_InitStruct.Mode = GPIO_MODE_OUTPUT_PP;
  GPIO_InitStruct.Pull = GPIO_NOPULL;
  GPIO_InitStruct.Speed = GPIO_SPEED_FREQ_HIGH;
  HAL_GPIO_Init(GPIOA, &GPIO_InitStruct);

  /*Configure GPIO pin : PB0 */
  GPIO_InitStruct.Pin = GPIO_PIN_0;
  GPIO_InitStruct.Mode = GPIO_MODE_OUTPUT_PP;
  GPIO_InitStruct.Pull = GPIO_NOPULL;
  GPIO_InitStruct.Speed = GPIO_SPEED_FREQ_HIGH;
  HAL_GPIO_Init(GPIOB, &GPIO_InitStruct);

}

void Error_Handler(void)
{
  __disable_irq();
  while (1)
  {
  }
}
